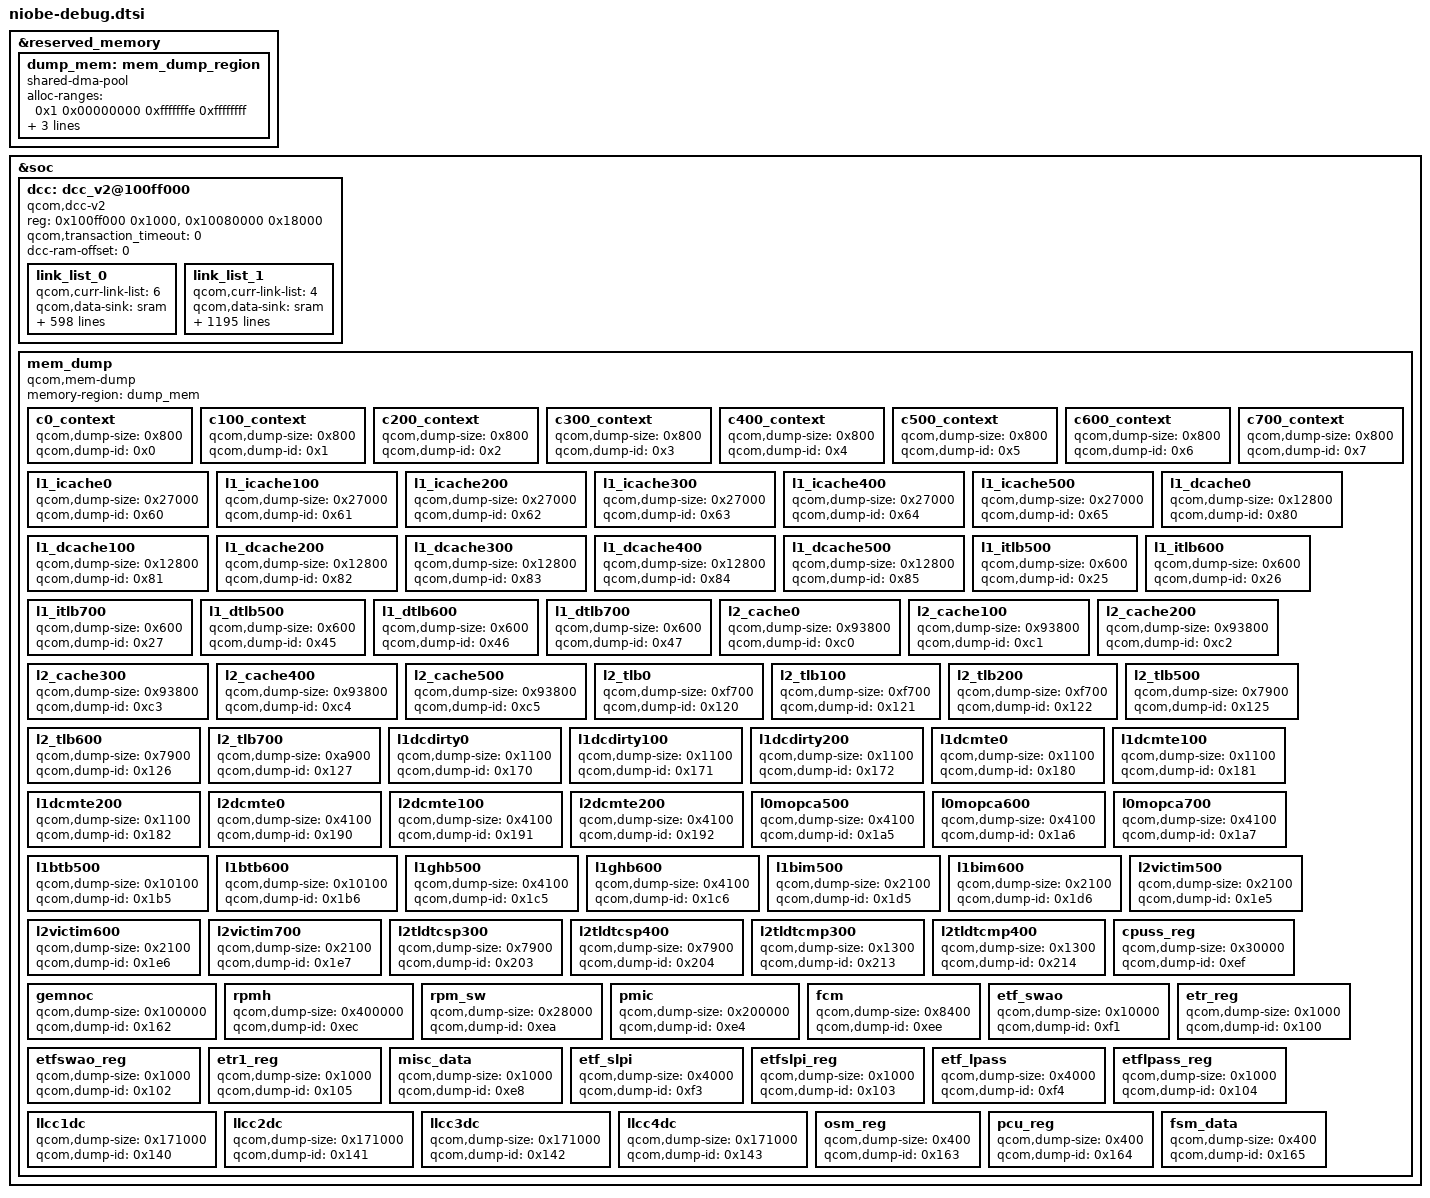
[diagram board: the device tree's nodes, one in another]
#include <dt-bindings/soc/qcom,dcc_v2.h>

&reserved_memory {
	#address-cells = <2>;
	#size-cells = <2>;
	ranges;

	dump_mem: mem_dump_region {
		compatible = "shared-dma-pool";
		alloc-ranges = <0x1 0x00000000 0xfffffffe 0xffffffff>;
		reusable;
		alignment = <0x0 0x400000>;
		size = <0 0x1800000>;
	};
};

&soc {
	dcc: dcc_v2@100ff000 {
		compatible = "qcom,dcc-v2";
		reg = <0x100ff000 0x1000>,
		      <0x10080000 0x18000>;

		qcom,transaction_timeout = <0>;

		reg-names = "dcc-base", "dcc-ram-base";
		dcc-ram-offset = <0>;

		link_list_0 {
			qcom,curr-link-list = <6>;
			qcom,data-sink = "sram";
			qcom,ap-qad-override;
			qcom,link-list = <DCC_READ 0x17421000 2 0>,
				<DCC_READ 0x3da0074 1 0>,
				<DCC_READ 0x3da0474 1 0>,
				<DCC_READ 0x3da0070 1 0>,
				<DCC_READ 0x15000474 1 0>,
				<DCC_READ 0x15000074 1 0>,
				<DCC_READ 0x15000070 1 0>,
				<DCC_READ 0x0c222004 1 0>,
				<DCC_READ 0x0c228014 1 0>,
				<DCC_READ 0x0c2280e0 1 0>,
				<DCC_READ 0x0c2280ec 1 0>,
				<DCC_READ 0x0c2280a0 16 0>,
				<DCC_READ 0x0c2280e8 1 0>,
				<DCC_READ 0x0c22813c 1 0>,
				<DCC_READ 0x0c223004 1 0>,
				<DCC_READ 0x0c229014 1 0>,
				<DCC_READ 0x0c2290e0 1 0>,
				<DCC_READ 0x0c2290ec 1 0>,
				<DCC_READ 0x0c2290a0 16 0>,
				<DCC_READ 0x0c2290e8 1 0>,
				<DCC_READ 0x0c22913c 1 0>,
				<DCC_READ 0x0c224004 1 0>,
				<DCC_READ 0x0c22a014 1 0>,
				<DCC_READ 0x0c22a0e0 1 0>,
				<DCC_READ 0x0c22a0ec 1 0>,
				<DCC_READ 0x0c22a0a0 16 0>,
				<DCC_READ 0x0c22a0e8 1 0>,
				<DCC_READ 0x0c22a13c 1 0>,
				<DCC_READ 0x17b70220 6 0>,
				<DCC_READ 0x17b702a0 6 0>,
				<DCC_READ 0x17b70320 1 0>,
				<DCC_READ 0x17b704a0 16 0>,
				<DCC_READ 0x17b70520 1 0>,
				<DCC_READ 0x17b70524 1 0>,
				<DCC_READ 0x17b70588 1 0>,
				<DCC_READ 0x17b70630 2 0>,
				<DCC_READ 0x17b70638 2 0>,
				<DCC_READ 0x17b70640 2 0>,
				<DCC_READ 0x17b71010 24 0>,
				<DCC_READ 0x17b71310 16 0>,
				<DCC_READ 0x17b71390 16 0>,
				<DCC_READ 0x17b72090 8 0>,
				<DCC_READ 0x17b744a0 16 0>,
				<DCC_READ 0x17b74520 1 0>,
				<DCC_READ 0x17b74588 1 0>,
				<DCC_READ 0x17b74630 2 0>,
				<DCC_READ 0x17b74638  2>,
				<DCC_READ 0x17b74640 2 0>,
				<DCC_READ 0x17b75010 24 0>,
				<DCC_READ 0x17b75310 16 0>,
				<DCC_READ 0x17b75390 16 0>,
				<DCC_READ 0x17b76090 8 0>,
				<DCC_READ 0xec80010 1 0>,
				<DCC_READ 0xec81000 1 0>,
				<DCC_READ 0xec81010 16 0>,
				<DCC_READ 0xec81050 4 0>,
				<DCC_READ 0xec81090 16 0>,
				<DCC_READ 0xec810d0 16 0>,
				<DCC_READ 0xec81110 16 0>,
				<DCC_READ 0xec81150 16 0>,
				<DCC_READ 0xec81550 1 0>,
				<DCC_READ 0x17800058 1 0>,
				<DCC_READ 0x17810058 1 0>,
				<DCC_READ 0x17820058 1 0>,
				<DCC_READ 0x17830058 1 0>,
				<DCC_READ 0x17840058 1 0>,
				<DCC_READ 0x17850058 1 0>,
				<DCC_READ 0x1780005c 1 0>,
				<DCC_READ 0x1781005c 1 0>,
				<DCC_READ 0x1782005c 1 0>,
				<DCC_READ 0x1783005c 1 0>,
				<DCC_READ 0x1784005c 1 0>,
				<DCC_READ 0x1785005c 1 0>,
				<DCC_READ 0x17800060 1 0>,
				<DCC_READ 0x17810060 1 0>,
				<DCC_READ 0x17820060 1 0>,
				<DCC_READ 0x17830060 1 0>,
				<DCC_READ 0x17840060 1 0>,
				<DCC_READ 0x17850060 1 0>,
				<DCC_READ 0x17800064 1 0>,
				<DCC_READ 0x17810064 1 0>,
				<DCC_READ 0x17820064 1 0>,
				<DCC_READ 0x17830064 1 0>,
				<DCC_READ 0x17840064 1 0>,
				<DCC_READ 0x17850064 1 0>,
				<DCC_READ 0x1740003c 1 0>,
				<DCC_READ 0x17a80000 1 0>,
				<DCC_READ 0x17a8002c 1 0>,
				<DCC_READ 0x17a84000 1 0>,
				<DCC_READ 0x17a8402c 1 0>,
				<DCC_READ 0x240a0000 1 0>,
				<DCC_READ 0x240a0004 1 0>,
				<DCC_READ 0x240a1000 1 0>,
				<DCC_READ 0x240a1004 1 0>,
				<DCC_READ 0xc201244 1 0>,
				<DCC_READ 0xc202244 1 0>,
				<DCC_READ 0x17ba3a84 2 0>,
				<DCC_READ 0x17b93a84 1 0>,
				<DCC_READ 0x17b00000 70 0>,
				<DCC_READ 0x17900908 1 0>,
				<DCC_READ 0x17900c18 1 0>,
				<DCC_READ 0x17901908 1 0>,
				<DCC_READ 0x17901c18 1 0>,
				<DCC_READ 0x17b90810 1 0>,
				<DCC_READ 0x17b90814 1 0>,
				<DCC_READ 0x17b90818 1 0>,
				<DCC_READ 0x17ba0810 1 0>,
				<DCC_READ 0x17ba0814 1 0>,
				<DCC_READ 0x17ba0818 1 0>,
				<DCC_READ 0x17b93500 40 0>,
				<DCC_READ 0x17ba3500 40 0>,
				<DCC_READ 0x17a80000 16 0>,
				<DCC_READ 0x17a82000 6 0>,
				<DCC_READ 0x17a84000 16 0>,
				<DCC_READ 0x17a86000 6 0>,
				<DCC_READ 0x17a88000 16 0>,
				<DCC_READ 0x17a8a000 6 0>,
				<DCC_READ 0x17800010  0>,
				<DCC_READ 0x17800024  0>,
				<DCC_READ 0x17800038 6 0>,
				<DCC_READ 0x17800058 4 0>,
				<DCC_READ 0x1780006c  0>,
				<DCC_READ 0x178000f0 2 0>,
				<DCC_READ 0x17810010  0>,
				<DCC_READ 0x17810024  0>,
				<DCC_READ 0x17810038 6 0>,
				<DCC_READ 0x17810058 4 0>,
				<DCC_READ 0x1781006c  0>,
				<DCC_READ 0x178100f0 2 0>,
				<DCC_READ 0x17820010  0>,
				<DCC_READ 0x17820024  0>,
				<DCC_READ 0x17820038 6 0>,
				<DCC_READ 0x17820058 4 0>,
				<DCC_READ 0x1782006c  0>,
				<DCC_READ 0x178200f0 2 0>,
				<DCC_READ 0x17830010  0>,
				<DCC_READ 0x17830024  0>,
				<DCC_READ 0x17830038 6 0>,
				<DCC_READ 0x17830058 4 0>,
				<DCC_READ 0x1783006c  0>,
				<DCC_READ 0x178300f0 2 0>,
				<DCC_READ 0x17840010  0>,
				<DCC_READ 0x17840010  0>,
				<DCC_READ 0x17840024  0>,
				<DCC_READ 0x17840038 6 0>,
				<DCC_READ 0x17840058 4 0>,
				<DCC_READ 0x1784006c  0>,
				<DCC_READ 0x178400f0 2 0>,
				<DCC_READ 0x17850024  0>,
				<DCC_READ 0x17850038 6 0>,
				<DCC_READ 0x17850058 4 0>,
				<DCC_READ 0x1785006c  0>,
				<DCC_READ 0x178500f0 2 0>,
				<DCC_READ 0x17880010  0>,
				<DCC_READ 0x17880024  0>,
				<DCC_READ 0x1788003c 5 0>,
				<DCC_READ 0x1788006c 7 0>,
				<DCC_READ 0x17880090 5 0>,
				<DCC_READ 0x178800e0 23 0>,
				<DCC_READ 0x17880140 2 0>,
				<DCC_READ 0x1788019c 2 0>,
				<DCC_READ 0x178801b4 6 0>,
				<DCC_READ 0x178801f0 5 0>,
				<DCC_READ 0x17880250 4 0>,
				<DCC_READ 0x17200104 29 0>,
				<DCC_READ 0x17200204 29 0>,
				<DCC_READ 0x17200384 29 0>,
				<DCC_READ 0x17220000 1 0>,
				<DCC_READ 0x17220008 1 0>,
				<DCC_READ 0x17220010 1 0>,
				<DCC_READ 0x17220018 1 0>,
				<DCC_READ 0x17220020 1 0>,
				<DCC_READ 0x17220028 1 0>,
				<DCC_READ 0x17220040 1 0>,
				<DCC_READ 0x17220048 1 0>,
				<DCC_READ 0x17220050 1 0>,
				<DCC_READ 0x17220060 1 0>,
				<DCC_READ 0x17220068 1 0>,
				<DCC_READ 0x17220080 1 0>,
				<DCC_READ 0x17220088 1 0>,
				<DCC_READ 0x17220090 1 0>,
				<DCC_READ 0x172200a0 1 0>,
				<DCC_READ 0x172200a8 1 0>,
				<DCC_READ 0x172200c0 1 0>,
				<DCC_READ 0x172200c8 1 0>,
				<DCC_READ 0x172200d0 1 0>,
				<DCC_READ 0x172200e0 1 0>,
				<DCC_READ 0x172200e8 1 0>,
				<DCC_READ 0x17220100 1 0>,
				<DCC_READ 0x17220108 1 0>,
				<DCC_READ 0x17220110 1 0>,
				<DCC_READ 0x17220120 1 0>,
				<DCC_READ 0x17220128 1 0>,
				<DCC_READ 0x17220140 1 0>,
				<DCC_READ 0x17220148 1 0>,
				<DCC_READ 0x17220150 1 0>,
				<DCC_READ 0x17220160 1 0>,
				<DCC_READ 0x17220168 1 0>,
				<DCC_READ 0x17220180 1 0>,
				<DCC_READ 0x17220188 1 0>,
				<DCC_READ 0x17220190 1 0>,
				<DCC_READ 0x172201a0 1 0>,
				<DCC_READ 0x172201a8 1 0>,
				<DCC_READ 0x172201c0 1 0>,
				<DCC_READ 0x172201c8 1 0>,
				<DCC_READ 0x172201d0 1 0>,
				<DCC_READ 0x172201e0 1 0>,
				<DCC_READ 0x172201e8 1 0>,
				<DCC_READ 0x17220200 1 0>,
				<DCC_READ 0x17220208 1 0>,
				<DCC_READ 0x17220210 1 0>,
				<DCC_READ 0x17220220 1 0>,
				<DCC_READ 0x17220228 1 0>,
				<DCC_READ 0x17220240 1 0>,
				<DCC_READ 0x17220248 1 0>,
				<DCC_READ 0x17220250 1 0>,
				<DCC_READ 0x17220260 1 0>,
				<DCC_READ 0x17220268 1 0>,
				<DCC_READ 0x17220280 1 0>,
				<DCC_READ 0x17220288 1 0>,
				<DCC_READ 0x17220290 1 0>,
				<DCC_READ 0x172202a0 1 0>,
				<DCC_READ 0x172202a8 1 0>,
				<DCC_READ 0x172202c0 1 0>,
				<DCC_READ 0x172202c8 1 0>,
				<DCC_READ 0x172202d0 1 0>,
				<DCC_READ 0x172202e0 1 0>,
				<DCC_READ 0x172202e8 1 0>,
				<DCC_READ 0x17220300 1 0>,
				<DCC_READ 0x17220308 1 0>,
				<DCC_READ 0x17220310 1 0>,
				<DCC_READ 0x17220320 1 0>,
				<DCC_READ 0x17220328 1 0>,
				<DCC_READ 0x17220340 1 0>,
				<DCC_READ 0x17220348 1 0>,
				<DCC_READ 0x17220350 1 0>,
				<DCC_READ 0x17220360 1 0>,
				<DCC_READ 0x17220368 1 0>,
				<DCC_READ 0x1722e000 1 0>,
				<DCC_READ 0x17d80100 200 0>,
				<DCC_READ 0x17d9001c 1 0>,
				<DCC_READ 0x17d900dc 1 0>,
				<DCC_READ 0x17d900e8 1 0>,
				<DCC_READ 0x17d90320 1 0>,
				<DCC_READ 0x17d9101c 1 0>,
				<DCC_READ 0x17d910dc 1 0>,
				<DCC_READ 0x17d910e8 1 0>,
				<DCC_READ 0x17d91320 1 0>,
				<DCC_READ 0x17d9201c 1 0>,
				<DCC_READ 0x17d920dc 1 0>,
				<DCC_READ 0x17d920e8 1 0>,
				<DCC_READ 0x17d92320 1 0>,
				<DCC_READ 0x17d9034c 1 0>,
				<DCC_READ 0x17d9134c 1 0>,
				<DCC_READ 0x17d9234c 1 0>,
				<DCC_READ 0x17880054 1 0>,
				<DCC_READ 0x17880000 1 0>,
				<DCC_READ 0x17a80000 1 0>,
				<DCC_READ 0x17d80000 3 0>,
				<DCC_READ 0x17d80010 2 0>,
				<DCC_READ 0x17d90000 4 0>,
				<DCC_READ 0x17d90014 2 0>,
				<DCC_READ 0x17d90024 22 0>,
				<DCC_READ 0x17d90080 5 0>,
				<DCC_READ 0x17d900b0 1 0>,
				<DCC_READ 0x17d900b8 2 0>,
				<DCC_READ 0x17d900d0 3 0>,
				<DCC_READ 0x17d900e0 2 0>,
				<DCC_READ 0x17d900ec 2 0>,
				<DCC_READ 0x17d90100 40 0>,
				<DCC_READ 0x17d90200 40 0>,
				<DCC_READ 0x17d90304 4 0>,
				<DCC_READ 0x17d90350 30 0>,
				<DCC_READ 0x17d903e0 2 0>,
				<DCC_READ 0x17d90404 1 0>,
				<DCC_READ 0x17d91000 2 0>,
				<DCC_READ 0x17d91014 2 0>,
				<DCC_READ 0x17d91024 22 0>,
				<DCC_READ 0x17d91080 6 0>,
				<DCC_READ 0x17d910b0 1 0>,
				<DCC_READ 0x17d910b8 2 0>,
				<DCC_READ 0x17d910d0 3 0>,
				<DCC_READ 0x17d910e0 2 0>,
				<DCC_READ 0x17d910ec 2 0>,
				<DCC_READ 0x17d91100 40 0>,
				<DCC_READ 0x17d91200 40 0>,
				<DCC_READ 0x17d91304 4 0>,
				<DCC_READ 0x17d91324 1 0>,
				<DCC_READ 0x17d91350 32 0>,
				<DCC_READ 0x17d913e0 3 0>,
				<DCC_READ 0x17d91404 1 0>,
				<DCC_READ 0x17d92000 4 0>,
				<DCC_READ 0x17d92014 2 0>,
				<DCC_READ 0x17d92024 22 0>,
				<DCC_READ 0x17d92080 7 0>,
				<DCC_READ 0x17d920b0 1 0>,
				<DCC_READ 0x17d920b8 2 0>,
				<DCC_READ 0x17d920d0 3 0>,
				<DCC_READ 0x17d920e0 2 0>,
				<DCC_READ 0x17d920ec 2 0>,
				<DCC_READ 0x17d92100 40 0>,
				<DCC_READ 0x17d92200 40 0>,
				<DCC_READ 0x17d92304 4 0>,
				<DCC_READ 0x17d92324 2 0>,
				<DCC_READ 0x17d92350 33 0>,
				<DCC_READ 0x17d923e0 4 0>,
				<DCC_READ 0x17d92404 1 0>,
				<DCC_READ 0x17d98000 8 0>,
				<DCC_READ 0x17d98020 2 0>,
				<DCC_READ 0x17d90020 1 0>,
				<DCC_READ 0x17d91020 1 0>,
				<DCC_READ 0x17d92020 1 0>,
				<DCC_READ 0x17d90300 1 0>,
				<DCC_READ 0x17d90340 1 0>,
				<DCC_READ 0x17d90410 1 0>,
				<DCC_READ 0x17d91008 1 0>,
				<DCC_READ 0x17d9100c 1 0>,
				<DCC_READ 0x17d91300 1 0>,
				<DCC_READ 0x17d91340 1 0>,
				<DCC_READ 0x17d91410 1 0>,
				<DCC_READ 0x17d92300 1 0>,
				<DCC_READ 0x17d92340 1 0>,
				<DCC_READ 0x17d92410 1 0>,
				<DCC_READ 0x17d8000c 1 0>,
				<DCC_READ 0x17d80018 1 0>,
				<DCC_READ 0xb200110  0>,
				<DCC_READ 0xb200900  0>,
				<DCC_READ 0xb201020 2 0>,
				<DCC_READ 0xb201030  0>,
				<DCC_READ 0xb20103c  0>,
				<DCC_READ 0xb201200 3 0>,
				<DCC_READ 0xb204510 2 0>,
				<DCC_READ 0xb204520  0>,
				<DCC_READ 0xb211024  0>,
				<DCC_READ 0xb221024  0>,
				<DCC_READ 0xb231024  0>,
				<DCC_READ 0x17a00010  0>,
				<DCC_READ 0x17a00030  0>,
				<DCC_READ 0x17a00038  0>,
				<DCC_READ 0x17a00040  0>,
				<DCC_READ 0x17a00048  0>,
				<DCC_READ 0x17a00400 3 0>,
				<DCC_READ 0x17a00408  0>,
				<DCC_READ 0xc2a8070 1 0>,
				<DCC_READ 0xc2a8074 1 0>,
				<DCC_READ 0xc2a8078 1 0>,
				<DCC_READ 0x123140 1 0>,
				<DCC_READ 0x11c004 2 0>,
				<DCC_READ 0x110018 5 0>,
				<DCC_READ 0x110030  0>,
				<DCC_READ 0x11c018 5 0>,
				<DCC_READ 0x11c030  0>,
				<DCC_READ 0x178040  0>,
				<DCC_READ 0x199014 5 0>,
				<DCC_READ 0x19902c  0>,
				<DCC_READ 0x19d014 5 0>,
				<DCC_READ 0x19d02c  0>,
				<DCC_READ 0x10c0000 4 0>,
				<DCC_READ 0x10c1000 2 0>,
				<DCC_READ 0x10c1010 7 0>,
				<DCC_READ 0x10c1100 3 0>,
				<DCC_READ 0x10c1110 5 0>,
				<DCC_READ 0x10c1130 2 0>,
				<DCC_READ 0x10c113c 2 0>,
				<DCC_READ 0x10c1148 3 0>,
				<DCC_READ 0x15002204  0>,
				<DCC_READ 0x150025dc  0>,
				<DCC_READ 0x15002670  0>,
				<DCC_READ 0x3da26b4  0>,
				<DCC_READ 0x126010 2 0>,
				<DCC_READ 0xadf0004 2 0>,
				<DCC_READ 0xadf0018 2 0>,
				<DCC_READ 0xadf0030 3 0>,
				<DCC_READ 0xadf004c 3 0>,
				<DCC_READ 0xadf0068  0>,
				<DCC_READ 0xadf0074  0>,
				<DCC_READ 0xadf0080 2 0>,
				<DCC_READ 0xadf0094 2 0>,
				<DCC_READ 0xadf00ac  0>,
				<DCC_READ 0xadf00b8 2 0>,
				<DCC_READ 0xadf00d0 3 0>,
				<DCC_READ 0xadf1004 2 0>,
				<DCC_READ 0xadf1018 2 0>,
				<DCC_READ 0xadf1030  0>,
				<DCC_READ 0xadf103c  0>,
				<DCC_READ 0xadf1048 3 0>,
				<DCC_READ 0xadf2004 2 0>,
				<DCC_READ 0xadf2018 2 0>,
				<DCC_READ 0xadf2030  0>,
				<DCC_READ 0xadf203c  0>,
				<DCC_READ 0xadf2048  0>,
				<DCC_READ 0xadf3000 2 0>,
				<DCC_READ 0xadf3018  0>,
				<DCC_READ 0xadf3024 3 0>,
				<DCC_READ 0xadf3040  0>,
				<DCC_READ 0xadf304c 4 0>,
				<DCC_READ 0xadf306c  0>,
				<DCC_READ 0xadf309c 2 0>,
				<DCC_READ 0xadf30b4  0>,
				<DCC_READ 0xadf30c0  0>,
				<DCC_READ 0xadf316c  0>,
				<DCC_READ 0xadf319c  0>,
				<DCC_READ 0xadf31a8 2 0>,
				<DCC_READ 0xadf31c0  0>,
				<DCC_READ 0xadf4020 3 0>,
				<DCC_READ 0xadf4038  0>,
				<DCC_READ 0xadf5170  0>,
				<DCC_READ 0x221c00a0 1 0>,
				<DCC_READ 0x221c00a4 1 0>,
				<DCC_READ 0x17400038 1 0>,
				<DCC_READ 0x17d98010 1 0>,
				<DCC_READ 0x1fc8000 1 0>,
				<DCC_READ 0x221c20a4 1 0>,
				<DCC_READ 0x129000  0>,
				<DCC_READ 0x12903c  0>,
				<DCC_READ 0x171004  0>,
				<DCC_READ 0x17100c 5 0>,
				<DCC_READ 0x171150  0>,
				<DCC_READ 0x17b000  0>,
				<DCC_READ 0x17b03c  0>,
				<DCC_READ 0x17c000  0>,
				<DCC_READ 0x17c03c  0>,
				<DCC_READ 0x17d000  0>,
				<DCC_READ 0x17d03c  0>,
				<DCC_READ 0x17e000  0>,
				<DCC_READ 0x17e03c  0>,
				<DCC_READ 0x186000  0>,
				<DCC_READ 0x18603c  0>,
				<DCC_READ 0x3d00000  0>,
				<DCC_READ 0x3d00008  0>,
				<DCC_READ 0x3d00020 6 0>,
				<DCC_READ 0x3d00040 4 0>,
				<DCC_READ 0x3d00054 2 0>,
				<DCC_READ 0x3d00060  0>,
				<DCC_READ 0x3d00068  0>,
				<DCC_READ 0x3d00070  0>,
				<DCC_READ 0x3d000a0 4 0>,
				<DCC_READ 0x3d000b4 13 0>,
				<DCC_READ 0x3d00100 20 0>,
				<DCC_READ 0x3d00188 5 0>,
				<DCC_READ 0x3d001a4 6 0>,
				<DCC_READ 0x3d001c4 2 0>,
				<DCC_READ 0x3d001d0  0>,
				<DCC_READ 0x3d001d8 2 0>,
				<DCC_READ 0x3d001fc 28 0>,
				<DCC_READ 0x3d00274 19 0>,
				<DCC_READ 0x3d002c8 35 0>,
				<DCC_READ 0x3d0035c 12 0>,
				<DCC_READ 0x3d00394 2 0>,
				<DCC_READ 0x3d003a4 9 0>,
				<DCC_READ 0x3d003d0 3 0>,
				<DCC_READ 0x3d003e4 16 0>,
				<DCC_READ 0x3d0042c 4 0>,
				<DCC_READ 0x3d00444  0>,
				<DCC_READ 0x3d00450 9 0>,
				<DCC_READ 0x3d0047c 3 0>,
				<DCC_READ 0x3d00494  0>,
				<DCC_READ 0x3d0049c  0>,
				<DCC_READ 0x3d004a4  0>,
				<DCC_READ 0x3d004ac 7 0>,
				<DCC_READ 0x3d004d0 5 0>,
				<DCC_READ 0x3d004e8  0>,
				<DCC_READ 0x3d004f0 4 0>,
				<DCC_READ 0x3d00508 15 0>,
				<DCC_READ 0x3d0054c 3 0>,
				<DCC_READ 0x3d00560 2 0>,
				<DCC_READ 0x3d00570  0>,
				<DCC_READ 0x3d00598 20 0>,
				<DCC_READ 0x3d00680  0>,
				<DCC_READ 0x3d00f80  0>,
				<DCC_READ 0x3d00fc0  0>,
				<DCC_READ 0x3d01100  0>,
				<DCC_READ 0x3d02000 31 0>,
				<DCC_READ 0x3d02080 4 0>,
				<DCC_READ 0x3d020d8 9 0>,
				<DCC_READ 0x3d02100 8 0>,
				<DCC_READ 0x3d0212c 5 0>,
				<DCC_READ 0x3d022c0 12 0>,
				<DCC_READ 0x3d02300 12 0>,
				<DCC_READ 0x3d0239c 5 0>,
				<DCC_READ 0x3d0f000 12 0>,
				<DCC_READ 0x3d0f100 3 0>,
				<DCC_READ 0x3d0f114 3 0>,
				<DCC_READ 0x3d0f124 6 0>,
				<DCC_READ 0x3d3c000 3 0>,
				<DCC_READ 0x3d3d000  0>,
				<DCC_READ 0x3d3e000 4 0>,
				<DCC_READ 0x3d3f000 2 0>,
				<DCC_READ 0x3d50000 21 0>,
				<DCC_READ 0x3d500d0  0>,
				<DCC_READ 0x3d500d8  0>,
				<DCC_READ 0x3d50100 3 0>,
				<DCC_READ 0x3d50110 2 0>,
				<DCC_READ 0x3d5011c  0>,
				<DCC_READ 0x3d50200 5 0>,
				<DCC_READ 0x3d50400 5 0>,
				<DCC_READ 0x3d50450  0>,
				<DCC_READ 0x3d50460 2 0>,
				<DCC_READ 0x3d50490 12 0>,
				<DCC_READ 0x3d50550  0>,
				<DCC_READ 0x3d50d00 2 0>,
				<DCC_READ 0x3d50d10  0>,
				<DCC_READ 0x3d50d18 13 0>,
				<DCC_READ 0x3d50fe0  0>,
				<DCC_READ 0x3d50ff8  0>,
				<DCC_READ 0x3d51010  0>,
				<DCC_READ 0x3d51028  0>,
				<DCC_READ 0x3d51280  0>,
				<DCC_READ 0x3d51520  0>,
				<DCC_READ 0x3d51538  0>,
				<DCC_READ 0x3d51550  0>,
				<DCC_READ 0x3d517c0  0>,
				<DCC_READ 0x3d51a60  0>,
				<DCC_READ 0x3d51a78  0>,
				<DCC_READ 0x3d51a90  0>,
				<DCC_READ 0x3d51aa8  0>,
				<DCC_READ 0x3d51d00  0>,
				<DCC_READ 0x3d51fa0  0>,
				<DCC_READ 0x3d51fb8  0>,
				<DCC_READ 0x3d52240  0>,
				<DCC_READ 0x3d52258  0>,
				<DCC_READ 0x3d524e0  0>,
				<DCC_READ 0x3d64000 13 0>,
				<DCC_READ 0x3d6403c  0>,
				<DCC_READ 0x3d66000 6 0>,
				<DCC_READ 0x3d67000  0>,
				<DCC_READ 0x3d68000 5 0>,
				<DCC_READ 0x3d68020 11 0>,
				<DCC_READ 0x3d68050  0>,
				<DCC_READ 0x3d6805c  0>,
				<DCC_READ 0x3d68064  0>,
				<DCC_READ 0x3d68088  0>,
				<DCC_READ 0x3d68090 6 0>,
				<DCC_READ 0x3d680fc 31 0>,
				<DCC_READ 0x3d68180 4 0>,
				<DCC_READ 0x3d68194 2 0>,
				<DCC_READ 0x3d681a0 15 0>,
				<DCC_READ 0x3d681e0 4 0>,
				<DCC_READ 0x3d69000 23 0>,
				<DCC_READ 0x3d69080 14 0>,
				<DCC_READ 0x3d690c0 2 0>,
				<DCC_READ 0x3d690d4  0>,
				<DCC_READ 0x3d690dc  0>,
				<DCC_READ 0x3d690e8  0>,
				<DCC_READ 0x3d69108  0>,
				<DCC_READ 0x3d69158 3 0>,
				<DCC_READ 0x3d6916c 3 0>,
				<DCC_READ 0x3d6917c 4 0>,
				<DCC_READ 0x3d7d000 12 0>,
				<DCC_READ 0x3d7d03c 3 0>,
				<DCC_READ 0x3d7d400  0>,
				<DCC_READ 0x3d7d41c  0>,
				<DCC_READ 0x3d7d424 3 0>,
				<DCC_READ 0x3d7dc58  0>,
				<DCC_READ 0x3d7dc94  0>,
				<DCC_READ 0x3d7dca4  0>,
				<DCC_READ 0x3d7dd58 2 0>,
				<DCC_READ 0x3d7df80 2 0>,
				<DCC_READ 0x3d7df90 2 0>,
				<DCC_READ 0x3d7dfa0 2 0>,
				<DCC_READ 0x3d7dfb0 2 0>,
				<DCC_READ 0x3d7e000 5 0>,
				<DCC_READ 0x3d7e01c 2 0>,
				<DCC_READ 0x3d7e02c 2 0>,
				<DCC_READ 0x3d7e03c  0>,
				<DCC_READ 0x3d7e044  0>,
				<DCC_READ 0x3d7e04c 5 0>,
				<DCC_READ 0x3d7e064 4 0>,
				<DCC_READ 0x3d7e090 13 0>,
				<DCC_READ 0x3d7e100 2 0>,
				<DCC_READ 0x3d7e130  0>,
				<DCC_READ 0x3d7e140  0>,
				<DCC_READ 0x3d7e500 2 0>,
				<DCC_READ 0x3d7e50c  0>,
				<DCC_READ 0x3d7e520  0>,
				<DCC_READ 0x3d7e53c  0>,
				<DCC_READ 0x3d7e550 2 0>,
				<DCC_READ 0x3d7e574  0>,
				<DCC_READ 0x3d7e5c0  0>,
				<DCC_READ 0x3d7e5f0 3 0>,
				<DCC_READ 0x3d7e600 2 0>,
				<DCC_READ 0x3d7e610 3 0>,
				<DCC_READ 0x3d7e648 2 0>,
				<DCC_READ 0x3d7e658 9 0>,
				<DCC_READ 0x3d7e700 16 0>,
				<DCC_READ 0x3d7e7c4  0>,
				<DCC_READ 0x3d7e7e0 3 0>,
				<DCC_READ 0x3d7e7f0  0>,
				<DCC_READ 0x3d7e800 4 0>,
				<DCC_READ 0x3d7f050  0>,
				<DCC_READ 0x3d7f060 2 0>,
				<DCC_READ 0x3d7f080  0>,
				<DCC_READ 0x3d7f090 3 0>,
				<DCC_READ 0x3d80080  0>,
				<DCC_READ 0x3d800d0 3 0>,
				<DCC_READ 0x3d80c80 3 0>,
				<DCC_READ 0x3d80c90 3 0>,
				<DCC_READ 0x3d80ca0 3 0>,
				<DCC_READ 0x3d80d40  0>,
				<DCC_READ 0x3d8e100 8 0>,
				<DCC_READ 0x3d8ec00 2 0>,
				<DCC_READ 0x3d8ec0c  0>,
				<DCC_READ 0x3d8ec14 10 0>,
				<DCC_READ 0x3d8ec40 4 0>,
				<DCC_READ 0x3d8ec54 2 0>,
				<DCC_READ 0x3d8eca0  0>,
				<DCC_READ 0x3d8ecc0  0>,
				<DCC_READ 0x3d9200c 3 0>,
				<DCC_READ 0x3d93000  0>,
				<DCC_READ 0x3d94000 3 0>,
				<DCC_READ 0x3d95000 5 0>,
				<DCC_READ 0x3d96000 5 0>,
				<DCC_READ 0x3d97000 5 0>,
				<DCC_READ 0x3d98000 5 0>,
				<DCC_READ 0x3d99000 7 0>,
				<DCC_READ 0x3d99054 9 0>,
				<DCC_READ 0x3d9907c 25 0>,
				<DCC_READ 0x3d990e4 3 0>,
				<DCC_READ 0x3d990f4 3 0>,
				<DCC_READ 0x3d9910c  0>,
				<DCC_READ 0x3d991e0 3 0>,
				<DCC_READ 0x3d99224 2 0>,
				<DCC_READ 0x3d99270 3 0>,
				<DCC_READ 0x3d99280 2 0>,
				<DCC_READ 0x3d99314 3 0>,
				<DCC_READ 0x3d993a0 3 0>,
				<DCC_READ 0x3d993e4 4 0>,
				<DCC_READ 0x3d9942c  0>,
				<DCC_READ 0x3d99470 3 0>,
				<DCC_READ 0x3d99500 12 0>,
				<DCC_READ 0x3d99550 3 0>,
				<DCC_READ 0x3d99560 5 0>,
				<DCC_READ 0x3d99578 2 0>,
				<DCC_READ 0x3d9958c  0>,
				<DCC_READ 0x3d995b4 7 0>,
				<DCC_READ 0x3d995d8  0>,
				<DCC_READ 0x3d995e0 3 0>,
				<DCC_READ 0x3d9e000  0>,
				<DCC_READ 0x3d9e040 5 0>,
				<DCC_READ 0x3d9e080 5 0>,
				<DCC_READ 0x3d9e0a0 3 0>,
				<DCC_READ 0x3d9e0c8 11 0>,
				<DCC_READ 0x3d9e0f8 26 0>,
				<DCC_READ 0x3d9e200 4 0>,
				<DCC_READ 0x3d9f000 2 0>,
				<DCC_READ 0x17421000 2 0>;
		};

		link_list_1 {
			qcom,curr-link-list = <4>;
			qcom,data-sink = "sram";
			qcom,ap-qad-override;
			qcom,link-list = <DCC_READ 0x17421000 2 0>,
				<DCC_READ 0x3da0074 1 0>,
				<DCC_READ 0x3da0474 1 0>,
				<DCC_READ 0x3da0070 1 0>,
				<DCC_READ 0x15000474 1 0>,
				<DCC_READ 0x15000074 1 0>,
				<DCC_READ 0x15000070 1 0>,
				<DCC_READ 0x2407701c  0>,
				<DCC_READ 0x24077030  0>,
				<DCC_READ 0x2408005c  0>,
				<DCC_READ 0x240800c8  0>,
				<DCC_READ 0x240800d4  0>,
				<DCC_READ 0x240800e0  0>,
				<DCC_READ 0x240800ec  0>,
				<DCC_READ 0x240800f8  0>,
				<DCC_READ 0x240801b4  0>,
				<DCC_READ 0x240a8120 5 0>,
				<DCC_READ 0x240a8144 2 0>,
				<DCC_READ 0x240a81c4 4 0>,
				<DCC_READ 0x240a81e4  0>,
				<DCC_READ 0x240a81f0  0>,
				<DCC_READ 0x240a81fc  0>,
				<DCC_READ 0x240a8208  0>,
				<DCC_READ 0x240a8258  0>,
				<DCC_READ 0x240a8278  0>,
				<DCC_READ 0x240a82e8  0>,
				<DCC_READ 0x240a8860 3 0>,
				<DCC_READ 0x240aa034 3 0>,
				<DCC_READ 0x240ba28c  0>,
				<DCC_READ 0x240ba294  0>,
				<DCC_READ 0x240ba29c  0>,
				<DCC_READ 0x24185100 4 0>,
				<DCC_READ 0x24187100  0>,
				<DCC_READ 0x2418c100  0>,
				<DCC_READ 0x24401e64  0>,
				<DCC_READ 0x24401ea0  0>,
				<DCC_READ 0x24403e64  0>,
				<DCC_READ 0x24403ea0  0>,
				<DCC_READ 0x2440527c  0>,
				<DCC_READ 0x24405290  0>,
				<DCC_READ 0x244054ec  0>,
				<DCC_READ 0x244054f4  0>,
				<DCC_READ 0x24405514  0>,
				<DCC_READ 0x2440551c  0>,
				<DCC_READ 0x24405524  0>,
				<DCC_READ 0x24405548  0>,
				<DCC_READ 0x24405550  0>,
				<DCC_READ 0x24405558  0>,
				<DCC_READ 0x244055b8  0>,
				<DCC_READ 0x244055c0  0>,
				<DCC_READ 0x244055ec  0>,
				<DCC_READ 0x24405688  0>,
				<DCC_READ 0x24405870  0>,
				<DCC_READ 0x244058a0  0>,
				<DCC_READ 0x244058a8  0>,
				<DCC_READ 0x244058b0  0>,
				<DCC_READ 0x244058b8  0>,
				<DCC_READ 0x244058d8 2 0>,
				<DCC_READ 0x244058f4  0>,
				<DCC_READ 0x244058fc  0>,
				<DCC_READ 0x24405920  0>,
				<DCC_READ 0x24405928  0>,
				<DCC_READ 0x24405944  0>,
				<DCC_READ 0x24406604  0>,
				<DCC_READ 0x2440660c  0>,
				<DCC_READ 0x24407010  0>,
				<DCC_READ 0x24440310  0>,
				<DCC_READ 0x24440400 2 0>,
				<DCC_READ 0x24440410 3 0>,
				<DCC_READ 0x24440428  0>,
				<DCC_READ 0x24440430  0>,
				<DCC_READ 0x24440440  0>,
				<DCC_READ 0x24440448  0>,
				<DCC_READ 0x244404a0  0>,
				<DCC_READ 0x244404b0 3 0>,
				<DCC_READ 0x244404d0 2 0>,
				<DCC_READ 0x2444341c  0>,
				<DCC_READ 0x24445804  0>,
				<DCC_READ 0x2444590c  0>,
				<DCC_READ 0x24445a14  0>,
				<DCC_READ 0x24445c1c  0>,
				<DCC_READ 0x24445c38  0>,
				<DCC_READ 0x24449100  0>,
				<DCC_READ 0x24449110  0>,
				<DCC_READ 0x24449120  0>,
				<DCC_READ 0x24449180 2 0>,
				<DCC_READ 0x24460618  0>,
				<DCC_READ 0x24460684  0>,
				<DCC_READ 0x2446068c  0>,
				<DCC_READ 0x24481e64  0>,
				<DCC_READ 0x24481ea0  0>,
				<DCC_READ 0x24483e64  0>,
				<DCC_READ 0x24483ea0  0>,
				<DCC_READ 0x2448527c  0>,
				<DCC_READ 0x24485290  0>,
				<DCC_READ 0x244854ec  0>,
				<DCC_READ 0x244854f4  0>,
				<DCC_READ 0x24485514  0>,
				<DCC_READ 0x2448551c  0>,
				<DCC_READ 0x24485524  0>,
				<DCC_READ 0x24485548  0>,
				<DCC_READ 0x24485550  0>,
				<DCC_READ 0x24485558  0>,
				<DCC_READ 0x244855b8  0>,
				<DCC_READ 0x244855c0  0>,
				<DCC_READ 0x244855ec  0>,
				<DCC_READ 0x24485688  0>,
				<DCC_READ 0x24485870  0>,
				<DCC_READ 0x244858a0  0>,
				<DCC_READ 0x244858a8  0>,
				<DCC_READ 0x244858b0  0>,
				<DCC_READ 0x244858b8  0>,
				<DCC_READ 0x244858d8 2 0>,
				<DCC_READ 0x244858f4  0>,
				<DCC_READ 0x244858fc  0>,
				<DCC_READ 0x24485920  0>,
				<DCC_READ 0x24485928  0>,
				<DCC_READ 0x24485944  0>,
				<DCC_READ 0x24486604  0>,
				<DCC_READ 0x2448660c  0>,
				<DCC_READ 0x24487010  0>,
				<DCC_READ 0x244c0310  0>,
				<DCC_READ 0x244c0400 2 0>,
				<DCC_READ 0x244c0410 3 0>,
				<DCC_READ 0x244c0428  0>,
				<DCC_READ 0x244c0430  0>,
				<DCC_READ 0x244c0440  0>,
				<DCC_READ 0x244c0448  0>,
				<DCC_READ 0x244c04a0  0>,
				<DCC_READ 0x244c04b0 3 0>,
				<DCC_READ 0x244c04d0 2 0>,
				<DCC_READ 0x244c341c  0>,
				<DCC_READ 0x244c5804  0>,
				<DCC_READ 0x244c590c  0>,
				<DCC_READ 0x244c5a14  0>,
				<DCC_READ 0x244c5c1c  0>,
				<DCC_READ 0x244c5c38  0>,
				<DCC_READ 0x244c9100  0>,
				<DCC_READ 0x244c9110  0>,
				<DCC_READ 0x244c9120  0>,
				<DCC_READ 0x244c9180 2 0>,
				<DCC_READ 0x244e0618  0>,
				<DCC_READ 0x244e0684  0>,
				<DCC_READ 0x244e068c  0>,
				<DCC_READ 0x24601e64  0>,
				<DCC_READ 0x24601ea0  0>,
				<DCC_READ 0x24603e64  0>,
				<DCC_READ 0x24603ea0  0>,
				<DCC_READ 0x2460527c  0>,
				<DCC_READ 0x24605290  0>,
				<DCC_READ 0x246054ec  0>,
				<DCC_READ 0x246054f4  0>,
				<DCC_READ 0x24605514  0>,
				<DCC_READ 0x2460551c  0>,
				<DCC_READ 0x24605524  0>,
				<DCC_READ 0x24605548  0>,
				<DCC_READ 0x24605550  0>,
				<DCC_READ 0x24605558  0>,
				<DCC_READ 0x246055b8  0>,
				<DCC_READ 0x246055c0  0>,
				<DCC_READ 0x246055ec  0>,
				<DCC_READ 0x24605688  0>,
				<DCC_READ 0x24605870  0>,
				<DCC_READ 0x246058a0  0>,
				<DCC_READ 0x246058a8  0>,
				<DCC_READ 0x246058b0  0>,
				<DCC_READ 0x246058b8  0>,
				<DCC_READ 0x246058d8 2 0>,
				<DCC_READ 0x246058f4  0>,
				<DCC_READ 0x246058fc  0>,
				<DCC_READ 0x24605920  0>,
				<DCC_READ 0x24605928  0>,
				<DCC_READ 0x24605944  0>,
				<DCC_READ 0x24606604  0>,
				<DCC_READ 0x2460660c  0>,
				<DCC_READ 0x24607010  0>,
				<DCC_READ 0x24640310  0>,
				<DCC_READ 0x24640400 2 0>,
				<DCC_READ 0x24640410 3 0>,
				<DCC_READ 0x24640428  0>,
				<DCC_READ 0x24640430  0>,
				<DCC_READ 0x24640440  0>,
				<DCC_READ 0x24640448  0>,
				<DCC_READ 0x246404a0  0>,
				<DCC_READ 0x246404b0 3 0>,
				<DCC_READ 0x246404d0 2 0>,
				<DCC_READ 0x2464341c  0>,
				<DCC_READ 0x24645804  0>,
				<DCC_READ 0x2464590c  0>,
				<DCC_READ 0x24645a14  0>,
				<DCC_READ 0x24645c1c  0>,
				<DCC_READ 0x24645c38  0>,
				<DCC_READ 0x24649100  0>,
				<DCC_READ 0x24649110  0>,
				<DCC_READ 0x24649120  0>,
				<DCC_READ 0x24649180 2 0>,
				<DCC_READ 0x24660618  0>,
				<DCC_READ 0x24660684  0>,
				<DCC_READ 0x2466068c  0>,
				<DCC_READ 0x24681e64  0>,
				<DCC_READ 0x24681ea0  0>,
				<DCC_READ 0x24683e64  0>,
				<DCC_READ 0x24683ea0  0>,
				<DCC_READ 0x2468527c  0>,
				<DCC_READ 0x24685290  0>,
				<DCC_READ 0x246854ec  0>,
				<DCC_READ 0x246854f4  0>,
				<DCC_READ 0x24685514  0>,
				<DCC_READ 0x2468551c  0>,
				<DCC_READ 0x24685524  0>,
				<DCC_READ 0x24685548  0>,
				<DCC_READ 0x24685550  0>,
				<DCC_READ 0x24685558  0>,
				<DCC_READ 0x246855b8  0>,
				<DCC_READ 0x246855c0  0>,
				<DCC_READ 0x246855ec  0>,
				<DCC_READ 0x24685688  0>,
				<DCC_READ 0x24685870  0>,
				<DCC_READ 0x246858a0  0>,
				<DCC_READ 0x246858a8  0>,
				<DCC_READ 0x246858b0  0>,
				<DCC_READ 0x246858b8  0>,
				<DCC_READ 0x246858d8 2 0>,
				<DCC_READ 0x246858f4  0>,
				<DCC_READ 0x246858fc  0>,
				<DCC_READ 0x24685920  0>,
				<DCC_READ 0x24685928  0>,
				<DCC_READ 0x24685944  0>,
				<DCC_READ 0x24686604  0>,
				<DCC_READ 0x2468660c  0>,
				<DCC_READ 0x24687010  0>,
				<DCC_READ 0x246c5804  0>,
				<DCC_READ 0x246c0310  0>,
				<DCC_READ 0x246c0400 2 0>,
				<DCC_READ 0x246c0410 3 0>,
				<DCC_READ 0x246c0428  0>,
				<DCC_READ 0x246c0430  0>,
				<DCC_READ 0x246c0440  0>,
				<DCC_READ 0x246c0448  0>,
				<DCC_READ 0x246c04a0  0>,
				<DCC_READ 0x246c04b0 3 0>,
				<DCC_READ 0x246c04d0 2 0>,
				<DCC_READ 0x246c341c  0>,
				<DCC_READ 0x246c590c  0>,
				<DCC_READ 0x246c5a14  0>,
				<DCC_READ 0x246c5c1c  0>,
				<DCC_READ 0x246c5c38  0>,
				<DCC_READ 0x246c9100  0>,
				<DCC_READ 0x246c9110  0>,
				<DCC_READ 0x246c9120  0>,
				<DCC_READ 0x246c9180 2 0>,
				<DCC_READ 0x246e0618  0>,
				<DCC_READ 0x246e0684  0>,
				<DCC_READ 0x246e068c  0>,
				<DCC_READ 0x24840310  0>,
				<DCC_READ 0x24840400 2 0>,
				<DCC_READ 0x24840410 3 0>,
				<DCC_READ 0x24840428  0>,
				<DCC_READ 0x24840430  0>,
				<DCC_READ 0x24840440  0>,
				<DCC_READ 0x24840448  0>,
				<DCC_READ 0x248404a0  0>,
				<DCC_READ 0x248404b0 3 0>,
				<DCC_READ 0x248404d0 2 0>,
				<DCC_READ 0x2484341c  0>,
				<DCC_READ 0x24845804  0>,
				<DCC_READ 0x2484590c  0>,
				<DCC_READ 0x24845a14  0>,
				<DCC_READ 0x24845c1c  0>,
				<DCC_READ 0x24845c38  0>,
				<DCC_READ 0x24849100  0>,
				<DCC_READ 0x24849110  0>,
				<DCC_READ 0x24849120  0>,
				<DCC_READ 0x24849180 2 0>,
				<DCC_READ 0x24860618  0>,
				<DCC_READ 0x24860684  0>,
				<DCC_READ 0x2486068c  0>,
				<DCC_READ 0x248c0310  0>,
				<DCC_READ 0x248c0400 2 0>,
				<DCC_READ 0x248c0410 3 0>,
				<DCC_READ 0x248c0428  0>,
				<DCC_READ 0x248c0430  0>,
				<DCC_READ 0x248c0440  0>,
				<DCC_READ 0x248c0448  0>,
				<DCC_READ 0x248c04a0  0>,
				<DCC_READ 0x248c04b0 3 0>,
				<DCC_READ 0x248c04d0 2 0>,
				<DCC_READ 0x248c341c  0>,
				<DCC_READ 0x248c5804  0>,
				<DCC_READ 0x248c590c  0>,
				<DCC_READ 0x248c5a14  0>,
				<DCC_READ 0x248c5c1c  0>,
				<DCC_READ 0x248c5c38  0>,
				<DCC_READ 0x248c9100  0>,
				<DCC_READ 0x248c9110  0>,
				<DCC_READ 0x248c9120  0>,
				<DCC_READ 0x248c9180 2 0>,
				<DCC_READ 0x248e0618  0>,
				<DCC_READ 0x248e0684  0>,
				<DCC_READ 0x248e068c  0>,
				<DCC_READ 0x25000004  0>,
				<DCC_READ 0x25001004  0>,
				<DCC_READ 0x25002004  0>,
				<DCC_READ 0x25003004  0>,
				<DCC_READ 0x25004004  0>,
				<DCC_READ 0x25005004  0>,
				<DCC_READ 0x25006004  0>,
				<DCC_READ 0x25007004  0>,
				<DCC_READ 0x25008004  0>,
				<DCC_READ 0x25009004  0>,
				<DCC_READ 0x2500a004  0>,
				<DCC_READ 0x2500b004  0>,
				<DCC_READ 0x2500c004  0>,
				<DCC_READ 0x2500d004  0>,
				<DCC_READ 0x2500e004  0>,
				<DCC_READ 0x2500f004  0>,
				<DCC_READ 0x25010004  0>,
				<DCC_READ 0x25011004  0>,
				<DCC_READ 0x25012004  0>,
				<DCC_READ 0x25013004  0>,
				<DCC_READ 0x25014004  0>,
				<DCC_READ 0x25015004  0>,
				<DCC_READ 0x25016004  0>,
				<DCC_READ 0x25017004  0>,
				<DCC_READ 0x25018004  0>,
				<DCC_READ 0x25019004  0>,
				<DCC_READ 0x2501a004  0>,
				<DCC_READ 0x2501b004  0>,
				<DCC_READ 0x2501c004  0>,
				<DCC_READ 0x2501d004  0>,
				<DCC_READ 0x2501e004  0>,
				<DCC_READ 0x2501f004  0>,
				<DCC_READ 0x25020348  0>,
				<DCC_READ 0x25020480  0>,
				<DCC_READ 0x25022400  0>,
				<DCC_READ 0x25023210  0>,
				<DCC_READ 0x25023220 4 0>,
				<DCC_READ 0x25023258 2 0>,
				<DCC_READ 0x25023308  0>,
				<DCC_READ 0x25023318  0>,
				<DCC_READ 0x25025000  0>,
				<DCC_READ 0x25025010  0>,
				<DCC_READ 0x25038100  0>,
				<DCC_READ 0x2503c030  0>,
				<DCC_READ 0x2504002c 4 0>,
				<DCC_READ 0x25040048 5 0>,
				<DCC_READ 0x25040060 2 0>,
				<DCC_READ 0x25040070 5 0>,
				<DCC_READ 0x25042044 3 0>,
				<DCC_READ 0x250420b0  0>,
				<DCC_READ 0x25042104  0>,
				<DCC_READ 0x25042114  0>,
				<DCC_READ 0x25048004 5 0>,
				<DCC_READ 0x2504c034  0>,
				<DCC_READ 0x25050020  0>,
				<DCC_READ 0x2506004c 8 0>,
				<DCC_READ 0x2507b03c  0>,
				<DCC_READ 0x2507b05c  0>,
				<DCC_READ 0x2507a01c 4 0>,
				<DCC_READ 0x2507a034 4 0>,
				<DCC_READ 0x2507a058  0>,
				<DCC_READ 0x2507a060  0>,
				<DCC_READ 0x2507a068  0>,
				<DCC_READ 0x2507a200  0>,
				<DCC_READ 0x2507b020  0>,
				<DCC_READ 0x2507b030 3 0>,
				<DCC_READ 0x2507b040 7 0>,
				<DCC_READ 0x2507b060 8 0>,
				<DCC_READ 0x2507b084  0>,
				<DCC_READ 0x2507b090 5 0>,
				<DCC_READ 0x2507b18c  0>,
				<DCC_READ 0x2507b1b0  0>,
				<DCC_READ 0x2507b204 13 0>,
				<DCC_READ 0x250a6010  0>,
				<DCC_READ 0x250a002c  0>,
				<DCC_READ 0x250a009c 2 0>,
				<DCC_READ 0x250a00a8 3 0>,
				<DCC_READ 0x250a00b8  0>,
				<DCC_READ 0x250a00c0 2 0>,
				<DCC_READ 0x250a00cc 4 0>,
				<DCC_READ 0x250a00e0  0>,
				<DCC_READ 0x250a00e8  0>,
				<DCC_READ 0x250a00f0  0>,
				<DCC_READ 0x250a00f0  0>,
				<DCC_READ 0x250a0100  0>,
				<DCC_READ 0x250a0108  0>,
				<DCC_READ 0x250a0110  0>,
				<DCC_READ 0x250a0118  0>,
				<DCC_READ 0x250a0120  0>,
				<DCC_READ 0x250a0128  0>,
				<DCC_READ 0x250a1010  0>,
				<DCC_READ 0x250a1070  0>,
				<DCC_READ 0x250a3004  0>,
				<DCC_READ 0x250a6008 2 0>,
				<DCC_READ 0x250a7008 3 0>,
				<DCC_READ 0x250a9004  0>,
				<DCC_READ 0x250a9010 3 0>,
				<DCC_READ 0x250a9020 3 0>,
				<DCC_READ 0x250a9030 3 0>,
				<DCC_READ 0x250a9040 3 0>,
				<DCC_READ 0x250a9050 3 0>,
				<DCC_READ 0x250aa004  0>,
				<DCC_READ 0x250aa010 3 0>,
				<DCC_READ 0x250aa020 3 0>,
				<DCC_READ 0x250aa030 3 0>,
				<DCC_READ 0x250aa040 3 0>,
				<DCC_READ 0x250aa050 3 0>,
				<DCC_READ 0x250b001c  0>,
				<DCC_READ 0x250b101c  0>,
				<DCC_READ 0x250b201c  0>,
				<DCC_READ 0x250b301c  0>,
				<DCC_READ 0x250b401c  0>,
				<DCC_READ 0x250b501c  0>,
				<DCC_READ 0x250b601c  0>,
				<DCC_READ 0x250b701c  0>,
				<DCC_READ 0x250b801c  0>,
				<DCC_READ 0x250b901c  0>,
				<DCC_READ 0x250ba01c  0>,
				<DCC_READ 0x250bb01c  0>,
				<DCC_READ 0x250bc01c  0>,
				<DCC_READ 0x250bd01c  0>,
				<DCC_READ 0x250be01c  0>,
				<DCC_READ 0x250bf01c  0>,
				<DCC_READ 0x25200004  0>,
				<DCC_READ 0x25201004  0>,
				<DCC_READ 0x25202004  0>,
				<DCC_READ 0x25203004  0>,
				<DCC_READ 0x25204004  0>,
				<DCC_READ 0x25205004  0>,
				<DCC_READ 0x25206004  0>,
				<DCC_READ 0x25207004  0>,
				<DCC_READ 0x25208004  0>,
				<DCC_READ 0x25209004  0>,
				<DCC_READ 0x2520a004  0>,
				<DCC_READ 0x2520b004  0>,
				<DCC_READ 0x2520c004  0>,
				<DCC_READ 0x2520d004  0>,
				<DCC_READ 0x2520e004  0>,
				<DCC_READ 0x2520f004  0>,
				<DCC_READ 0x25210004  0>,
				<DCC_READ 0x25211004  0>,
				<DCC_READ 0x25212004  0>,
				<DCC_READ 0x25213004  0>,
				<DCC_READ 0x25214004  0>,
				<DCC_READ 0x25215004  0>,
				<DCC_READ 0x25216004  0>,
				<DCC_READ 0x25217004  0>,
				<DCC_READ 0x25218004  0>,
				<DCC_READ 0x25219004  0>,
				<DCC_READ 0x2521a004  0>,
				<DCC_READ 0x2521b004  0>,
				<DCC_READ 0x2521c004  0>,
				<DCC_READ 0x2521d004  0>,
				<DCC_READ 0x2521e004  0>,
				<DCC_READ 0x2521f004  0>,
				<DCC_READ 0x25220348  0>,
				<DCC_READ 0x25220480  0>,
				<DCC_READ 0x25222400  0>,
				<DCC_READ 0x25223210  0>,
				<DCC_READ 0x25223220 4 0>,
				<DCC_READ 0x25223258 2 0>,
				<DCC_READ 0x25223308  0>,
				<DCC_READ 0x25223318  0>,
				<DCC_READ 0x25225000  0>,
				<DCC_READ 0x25225010  0>,
				<DCC_READ 0x25238100  0>,
				<DCC_READ 0x2523c030  0>,
				<DCC_READ 0x2524002c 4 0>,
				<DCC_READ 0x25240048 5 0>,
				<DCC_READ 0x25240060 2 0>,
				<DCC_READ 0x25240070 5 0>,
				<DCC_READ 0x25242044 3 0>,
				<DCC_READ 0x252420b0  0>,
				<DCC_READ 0x25242104  0>,
				<DCC_READ 0x25242114  0>,
				<DCC_READ 0x25248004 5 0>,
				<DCC_READ 0x2524c034  0>,
				<DCC_READ 0x25250020  0>,
				<DCC_READ 0x2526004c 8 0>,
				<DCC_READ 0x2527b03c  0>,
				<DCC_READ 0x2527b05c  0>,
				<DCC_READ 0x2527a01c 4 0>,
				<DCC_READ 0x2527a034 4 0>,
				<DCC_READ 0x2527a058  0>,
				<DCC_READ 0x2527a060  0>,
				<DCC_READ 0x2527a068  0>,
				<DCC_READ 0x2527a200  0>,
				<DCC_READ 0x2527b020  0>,
				<DCC_READ 0x2527b030 3 0>,
				<DCC_READ 0x2527b040 7 0>,
				<DCC_READ 0x2527b060 8 0>,
				<DCC_READ 0x2527b084  0>,
				<DCC_READ 0x2527b090 5 0>,
				<DCC_READ 0x2527b18c  0>,
				<DCC_READ 0x2527b1b0  0>,
				<DCC_READ 0x2527b204 13 0>,
				<DCC_READ 0x252a002c  0>,
				<DCC_READ 0x252a009c 2 0>,
				<DCC_READ 0x252a00a8 3 0>,
				<DCC_READ 0x252a00b8  0>,
				<DCC_READ 0x252a00c0 2 0>,
				<DCC_READ 0x252a00cc 4 0>,
				<DCC_READ 0x252a00e0  0>,
				<DCC_READ 0x252a00e8  0>,
				<DCC_READ 0x252a00f0  0>,
				<DCC_READ 0x252a00f0  0>,
				<DCC_READ 0x252a0100  0>,
				<DCC_READ 0x252a0108  0>,
				<DCC_READ 0x252a0110  0>,
				<DCC_READ 0x252a0118  0>,
				<DCC_READ 0x252a0120  0>,
				<DCC_READ 0x252a0128  0>,
				<DCC_READ 0x252a1010  0>,
				<DCC_READ 0x252a1070  0>,
				<DCC_READ 0x252a3004  0>,
				<DCC_READ 0x252a6008 3 0>,
				<DCC_READ 0x252a7008 3 0>,
				<DCC_READ 0x252a9004  0>,
				<DCC_READ 0x252a9010 3 0>,
				<DCC_READ 0x252a9020 3 0>,
				<DCC_READ 0x252a9030 3 0>,
				<DCC_READ 0x252a9040 3 0>,
				<DCC_READ 0x252a9050 3 0>,
				<DCC_READ 0x252aa004  0>,
				<DCC_READ 0x252aa010 3 0>,
				<DCC_READ 0x252aa020 3 0>,
				<DCC_READ 0x252aa030 3 0>,
				<DCC_READ 0x252aa040 3 0>,
				<DCC_READ 0x252aa050 3 0>,
				<DCC_READ 0x252b001c  0>,
				<DCC_READ 0x252b101c  0>,
				<DCC_READ 0x252b201c  0>,
				<DCC_READ 0x252b301c  0>,
				<DCC_READ 0x252b401c  0>,
				<DCC_READ 0x252b501c  0>,
				<DCC_READ 0x252b601c  0>,
				<DCC_READ 0x252b701c  0>,
				<DCC_READ 0x252b801c  0>,
				<DCC_READ 0x252b901c  0>,
				<DCC_READ 0x252ba01c  0>,
				<DCC_READ 0x252bb01c  0>,
				<DCC_READ 0x252bc01c  0>,
				<DCC_READ 0x252bd01c  0>,
				<DCC_READ 0x252be01c  0>,
				<DCC_READ 0x252bf01c  0>,
				<DCC_READ 0x25400004  0>,
				<DCC_READ 0x25401004  0>,
				<DCC_READ 0x25402004  0>,
				<DCC_READ 0x25403004  0>,
				<DCC_READ 0x25404004  0>,
				<DCC_READ 0x25405004  0>,
				<DCC_READ 0x25406004  0>,
				<DCC_READ 0x25407004  0>,
				<DCC_READ 0x25408004  0>,
				<DCC_READ 0x25409004  0>,
				<DCC_READ 0x2540a004  0>,
				<DCC_READ 0x2540b004  0>,
				<DCC_READ 0x2540c004  0>,
				<DCC_READ 0x2540d004  0>,
				<DCC_READ 0x2540e004  0>,
				<DCC_READ 0x2540f004  0>,
				<DCC_READ 0x25410004  0>,
				<DCC_READ 0x25411004  0>,
				<DCC_READ 0x25412004  0>,
				<DCC_READ 0x25413004  0>,
				<DCC_READ 0x25414004  0>,
				<DCC_READ 0x25415004  0>,
				<DCC_READ 0x25416004  0>,
				<DCC_READ 0x25417004  0>,
				<DCC_READ 0x25418004  0>,
				<DCC_READ 0x25419004  0>,
				<DCC_READ 0x2541a004  0>,
				<DCC_READ 0x2541b004  0>,
				<DCC_READ 0x2541c004  0>,
				<DCC_READ 0x2541d004  0>,
				<DCC_READ 0x2541e004  0>,
				<DCC_READ 0x2541f004  0>,
				<DCC_READ 0x25420348  0>,
				<DCC_READ 0x25420480  0>,
				<DCC_READ 0x25422400  0>,
				<DCC_READ 0x25423210  0>,
				<DCC_READ 0x25423220 4 0>,
				<DCC_READ 0x25423258 2 0>,
				<DCC_READ 0x25423308  0>,
				<DCC_READ 0x25423318  0>,
				<DCC_READ 0x25425000  0>,
				<DCC_READ 0x25425010  0>,
				<DCC_READ 0x25438100  0>,
				<DCC_READ 0x2543c030  0>,
				<DCC_READ 0x2544002c 4 0>,
				<DCC_READ 0x25440048 5 0>,
				<DCC_READ 0x25440060 2 0>,
				<DCC_READ 0x25440070 5 0>,
				<DCC_READ 0x25442044 3 0>,
				<DCC_READ 0x254420b0  0>,
				<DCC_READ 0x25442104  0>,
				<DCC_READ 0x25442114  0>,
				<DCC_READ 0x25448004 5 0>,
				<DCC_READ 0x2544c034  0>,
				<DCC_READ 0x25450020  0>,
				<DCC_READ 0x2546004c 8 0>,
				<DCC_READ 0x2547b03c  0>,
				<DCC_READ 0x2547b05c  0>,
				<DCC_READ 0x2547a01c 4 0>,
				<DCC_READ 0x2547a034 4 0>,
				<DCC_READ 0x2547a058  0>,
				<DCC_READ 0x2547a060  0>,
				<DCC_READ 0x2547a068  0>,
				<DCC_READ 0x2547a200  0>,
				<DCC_READ 0x2547b020  0>,
				<DCC_READ 0x2547b030 3 0>,
				<DCC_READ 0x2547b040 7 0>,
				<DCC_READ 0x2547b060 8 0>,
				<DCC_READ 0x2547b084  0>,
				<DCC_READ 0x2547b090 5 0>,
				<DCC_READ 0x2547b18c  0>,
				<DCC_READ 0x2547b1b0  0>,
				<DCC_READ 0x2547b204 13 0>,
				<DCC_READ 0x254a002c  0>,
				<DCC_READ 0x254a009c 2 0>,
				<DCC_READ 0x254a00a8 3 0>,
				<DCC_READ 0x254a00b8  0>,
				<DCC_READ 0x254a00c0 2 0>,
				<DCC_READ 0x254a00cc 4 0>,
				<DCC_READ 0x254a00e0  0>,
				<DCC_READ 0x254a00e8  0>,
				<DCC_READ 0x254a00f0  0>,
				<DCC_READ 0x254a00f0  0>,
				<DCC_READ 0x254a0100  0>,
				<DCC_READ 0x254a0108  0>,
				<DCC_READ 0x254a0110  0>,
				<DCC_READ 0x254a0118  0>,
				<DCC_READ 0x254a0120  0>,
				<DCC_READ 0x254a0128  0>,
				<DCC_READ 0x254a1010  0>,
				<DCC_READ 0x254a1070  0>,
				<DCC_READ 0x254a3004  0>,
				<DCC_READ 0x254a6008 3 0>,
				<DCC_READ 0x254a7008 3 0>,
				<DCC_READ 0x254a9004  0>,
				<DCC_READ 0x254a9010 3 0>,
				<DCC_READ 0x254a9020 3 0>,
				<DCC_READ 0x254a9030 3 0>,
				<DCC_READ 0x254a9040 3 0>,
				<DCC_READ 0x254a9050 3 0>,
				<DCC_READ 0x254aa004  0>,
				<DCC_READ 0x254aa010 3 0>,
				<DCC_READ 0x254aa020 3 0>,
				<DCC_READ 0x254aa030 3 0>,
				<DCC_READ 0x254aa040 3 0>,
				<DCC_READ 0x254aa050 3 0>,
				<DCC_READ 0x254b001c  0>,
				<DCC_READ 0x254b101c  0>,
				<DCC_READ 0x254b201c  0>,
				<DCC_READ 0x254b301c  0>,
				<DCC_READ 0x254b401c  0>,
				<DCC_READ 0x254b501c  0>,
				<DCC_READ 0x254b601c  0>,
				<DCC_READ 0x254b701c  0>,
				<DCC_READ 0x254b801c  0>,
				<DCC_READ 0x254b901c  0>,
				<DCC_READ 0x254ba01c  0>,
				<DCC_READ 0x254bb01c  0>,
				<DCC_READ 0x254bc01c  0>,
				<DCC_READ 0x254bd01c  0>,
				<DCC_READ 0x254be01c  0>,
				<DCC_READ 0x254bf01c  0>,
				<DCC_READ 0x25600004  0>,
				<DCC_READ 0x25601004  0>,
				<DCC_READ 0x25602004  0>,
				<DCC_READ 0x25603004  0>,
				<DCC_READ 0x25604004  0>,
				<DCC_READ 0x25605004  0>,
				<DCC_READ 0x25606004  0>,
				<DCC_READ 0x25607004  0>,
				<DCC_READ 0x25608004  0>,
				<DCC_READ 0x25609004  0>,
				<DCC_READ 0x2560a004  0>,
				<DCC_READ 0x2560b004  0>,
				<DCC_READ 0x2560c004  0>,
				<DCC_READ 0x2560d004  0>,
				<DCC_READ 0x2560e004  0>,
				<DCC_READ 0x2560f004  0>,
				<DCC_READ 0x25610004  0>,
				<DCC_READ 0x25611004  0>,
				<DCC_READ 0x25612004  0>,
				<DCC_READ 0x25613004  0>,
				<DCC_READ 0x25614004  0>,
				<DCC_READ 0x25615004  0>,
				<DCC_READ 0x25616004  0>,
				<DCC_READ 0x25617004  0>,
				<DCC_READ 0x25618004  0>,
				<DCC_READ 0x25619004  0>,
				<DCC_READ 0x2561a004  0>,
				<DCC_READ 0x2561b004  0>,
				<DCC_READ 0x2561c004  0>,
				<DCC_READ 0x2561d004  0>,
				<DCC_READ 0x2561e004  0>,
				<DCC_READ 0x2561f004  0>,
				<DCC_READ 0x25620348  0>,
				<DCC_READ 0x25620480  0>,
				<DCC_READ 0x25622400  0>,
				<DCC_READ 0x25623210  0>,
				<DCC_READ 0x25623220 4 0>,
				<DCC_READ 0x25623258 2 0>,
				<DCC_READ 0x25623308  0>,
				<DCC_READ 0x25623318  0>,
				<DCC_READ 0x25625000  0>,
				<DCC_READ 0x25625010  0>,
				<DCC_READ 0x25638100  0>,
				<DCC_READ 0x2563c030  0>,
				<DCC_READ 0x2564002c 4 0>,
				<DCC_READ 0x25640048 5 0>,
				<DCC_READ 0x25640060 2 0>,
				<DCC_READ 0x25640070 5 0>,
				<DCC_READ 0x25642044 3 0>,
				<DCC_READ 0x256420b0  0>,
				<DCC_READ 0x25642104  0>,
				<DCC_READ 0x25642114  0>,
				<DCC_READ 0x25648004 5 0>,
				<DCC_READ 0x2564c034  0>,
				<DCC_READ 0x25650020  0>,
				<DCC_READ 0x2566004c 8 0>,
				<DCC_READ 0x2567b03c  0>,
				<DCC_READ 0x2567b05c  0>,
				<DCC_READ 0x2567a01c 4 0>,
				<DCC_READ 0x2567a034 4 0>,
				<DCC_READ 0x2567a058  0>,
				<DCC_READ 0x2567a060  0>,
				<DCC_READ 0x2567a068  0>,
				<DCC_READ 0x2567a200  0>,
				<DCC_READ 0x2567b020  0>,
				<DCC_READ 0x2567b030 3 0>,
				<DCC_READ 0x2567b040 7 0>,
				<DCC_READ 0x2567b060 8 0>,
				<DCC_READ 0x2567b084  0>,
				<DCC_READ 0x2567b090 5 0>,
				<DCC_READ 0x2567b18c  0>,
				<DCC_READ 0x2567b1b0  0>,
				<DCC_READ 0x2567b204 13 0>,
				<DCC_READ 0x256a002c  0>,
				<DCC_READ 0x256a009c 2 0>,
				<DCC_READ 0x256a00a8 3 0>,
				<DCC_READ 0x256a00b8  0>,
				<DCC_READ 0x256a00c0 2 0>,
				<DCC_READ 0x256a00cc 4 0>,
				<DCC_READ 0x256a00e0  0>,
				<DCC_READ 0x256a00e8  0>,
				<DCC_READ 0x256a00f0  0>,
				<DCC_READ 0x256a00f0  0>,
				<DCC_READ 0x256a0100  0>,
				<DCC_READ 0x256a0108  0>,
				<DCC_READ 0x256a0110  0>,
				<DCC_READ 0x256a0118  0>,
				<DCC_READ 0x256a0120  0>,
				<DCC_READ 0x256a0128  0>,
				<DCC_READ 0x256a1010  0>,
				<DCC_READ 0x256a1070  0>,
				<DCC_READ 0x256a3004  0>,
				<DCC_READ 0x256a6008 3 0>,
				<DCC_READ 0x256a7008 3 0>,
				<DCC_READ 0x256a9004  0>,
				<DCC_READ 0x256a9010 3 0>,
				<DCC_READ 0x256a9020 3 0>,
				<DCC_READ 0x256a9030 3 0>,
				<DCC_READ 0x256a9040 3 0>,
				<DCC_READ 0x256a9050 3 0>,
				<DCC_READ 0x256aa004  0>,
				<DCC_READ 0x256aa010 3 0>,
				<DCC_READ 0x256aa020 3 0>,
				<DCC_READ 0x256aa030 3 0>,
				<DCC_READ 0x256aa040 3 0>,
				<DCC_READ 0x256aa050 3 0>,
				<DCC_READ 0x256b001c  0>,
				<DCC_READ 0x256b101c  0>,
				<DCC_READ 0x256b201c  0>,
				<DCC_READ 0x256b301c  0>,
				<DCC_READ 0x256b401c  0>,
				<DCC_READ 0x256b501c  0>,
				<DCC_READ 0x256b601c  0>,
				<DCC_READ 0x256b701c  0>,
				<DCC_READ 0x256b801c  0>,
				<DCC_READ 0x256b901c  0>,
				<DCC_READ 0x256ba01c  0>,
				<DCC_READ 0x256bb01c  0>,
				<DCC_READ 0x256bc01c  0>,
				<DCC_READ 0x256bd01c  0>,
				<DCC_READ 0x256be01c  0>,
				<DCC_READ 0x256bf01c  0>,
				<DCC_READ 0x25820348  0>,
				<DCC_READ 0x25820480  0>,
				<DCC_READ 0x25822400  0>,
				<DCC_READ 0x25823220 4 0>,
				<DCC_READ 0x25823258 2 0>,
				<DCC_READ 0x25823308  0>,
				<DCC_READ 0x25823318  0>,
				<DCC_READ 0x25838100  0>,
				<DCC_READ 0x2583c030  0>,
				<DCC_READ 0x25842044 3 0>,
				<DCC_READ 0x258420b0  0>,
				<DCC_READ 0x25842104  0>,
				<DCC_READ 0x25842114  0>,
				<DCC_READ 0x25848004 5 0>,
				<DCC_READ 0x2584c034  0>,
				<DCC_READ 0x25850020  0>,
				<DCC_READ 0x2586004c 8 0>,
				<DCC_READ 0x258a4040 48 0>,
				<DCC_READ 0x258b0000  0>,
				<DCC_READ 0x258b005c  0>,
				<DCC_READ 0x258b1000  0>,
				<DCC_READ 0x258b105c  0>,
				<DCC_READ 0x258b2000  0>,
				<DCC_READ 0x258b205c  0>,
				<DCC_READ 0x258b3000  0>,
				<DCC_READ 0x258b305c  0>,
				<DCC_READ 0x258b4000  0>,
				<DCC_READ 0x258b405c  0>,
				<DCC_READ 0x258b5000  0>,
				<DCC_READ 0x258b505c  0>,
				<DCC_READ 0x258b6000  0>,
				<DCC_READ 0x258b605c  0>,
				<DCC_READ 0x258b7000  0>,
				<DCC_READ 0x258b705c  0>,
				<DCC_READ 0x258b8000  0>,
				<DCC_READ 0x258b805c  0>,
				<DCC_READ 0x258b9000  0>,
				<DCC_READ 0x258b905c  0>,
				<DCC_READ 0x258ba000  0>,
				<DCC_READ 0x258ba05c  0>,
				<DCC_READ 0x258bb000  0>,
				<DCC_READ 0x258bb05c  0>,
				<DCC_READ 0x258bc000  0>,
				<DCC_READ 0x258bc05c  0>,
				<DCC_READ 0x258bd000  0>,
				<DCC_READ 0x258bd05c  0>,
				<DCC_READ 0x258be000  0>,
				<DCC_READ 0x258be05c  0>,
				<DCC_READ 0x258bf000  0>,
				<DCC_READ 0x258bf05c  0>,
				<DCC_READ 0x25a00004  0>,
				<DCC_READ 0x25a01004  0>,
				<DCC_READ 0x25a02004  0>,
				<DCC_READ 0x25a03004  0>,
				<DCC_READ 0x25a04004  0>,
				<DCC_READ 0x25a05004  0>,
				<DCC_READ 0x25a06004  0>,
				<DCC_READ 0x25a07004  0>,
				<DCC_READ 0x25a08004  0>,
				<DCC_READ 0x25a09004  0>,
				<DCC_READ 0x25a0a004  0>,
				<DCC_READ 0x25a0b004  0>,
				<DCC_READ 0x25a0c004  0>,
				<DCC_READ 0x25a0d004  0>,
				<DCC_READ 0x25a0e004  0>,
				<DCC_READ 0x25a0f004  0>,
				<DCC_READ 0x25a10004  0>,
				<DCC_READ 0x25a11004  0>,
				<DCC_READ 0x25a12004  0>,
				<DCC_READ 0x25a13004  0>,
				<DCC_READ 0x25a14004  0>,
				<DCC_READ 0x25a15004  0>,
				<DCC_READ 0x25a16004  0>,
				<DCC_READ 0x25a17004  0>,
				<DCC_READ 0x25a18004  0>,
				<DCC_READ 0x25a19004  0>,
				<DCC_READ 0x25a1a004  0>,
				<DCC_READ 0x25a1b004  0>,
				<DCC_READ 0x25a1c004  0>,
				<DCC_READ 0x25a1d004  0>,
				<DCC_READ 0x25a1e004  0>,
				<DCC_READ 0x25a1f004  0>,
				<DCC_READ 0x25a20348  0>,
				<DCC_READ 0x25a20480  0>,
				<DCC_READ 0x25a22400  0>,
				<DCC_READ 0x25a23220 4 0>,
				<DCC_READ 0x25a23258 2 0>,
				<DCC_READ 0x25a23308  0>,
				<DCC_READ 0x25a23318  0>,
				<DCC_READ 0x25a38100  0>,
				<DCC_READ 0x25a3c030  0>,
				<DCC_READ 0x25a42044 3 0>,
				<DCC_READ 0x25a420b0  0>,
				<DCC_READ 0x25a42104  0>,
				<DCC_READ 0x25a42114  0>,
				<DCC_READ 0x25a48004 5 0>,
				<DCC_READ 0x25a4c034  0>,
				<DCC_READ 0x25a50020  0>,
				<DCC_READ 0x25a6004c 8 0>,
				<DCC_READ 0x2503400c  0>,
				<DCC_READ 0x25821004  0>,
				<DCC_READ 0x2582100c  0>,
				<DCC_READ 0x25821014  0>,
				<DCC_READ 0x2582101c  0>,
				<DCC_READ 0x25821024  0>,
				<DCC_READ 0x2582102c  0>,
				<DCC_READ 0x25821034  0>,
				<DCC_READ 0x2582103c  0>,
				<DCC_READ 0x25821044  0>,
				<DCC_READ 0x2582104c  0>,
				<DCC_READ 0x25821054  0>,
				<DCC_READ 0x2582105c  0>,
				<DCC_READ 0x25821064  0>,
				<DCC_READ 0x2582106c  0>,
				<DCC_READ 0x25821074  0>,
				<DCC_READ 0x2582107c  0>,
				<DCC_READ 0x25821084  0>,
				<DCC_READ 0x2582108c  0>,
				<DCC_READ 0x25821094  0>,
				<DCC_READ 0x2582109c  0>,
				<DCC_READ 0x258210a4  0>,
				<DCC_READ 0x258210ac  0>,
				<DCC_READ 0x258210b4  0>,
				<DCC_READ 0x258210bc  0>,
				<DCC_READ 0x258210c4  0>,
				<DCC_READ 0x258210cc  0>,
				<DCC_READ 0x258210d4  0>,
				<DCC_READ 0x258210dc  0>,
				<DCC_READ 0x258210e4  0>,
				<DCC_READ 0x258210ec  0>,
				<DCC_READ 0x258210f4  0>,
				<DCC_READ 0x258210fc  0>,
				<DCC_READ 0x24102008  0>,
				<DCC_READ 0x24102010  0>,
				<DCC_READ 0x24102018  0>,
				<DCC_READ 0x24102020 6 0>,
				<DCC_READ 0x24102408  0>,
				<DCC_READ 0x24102410  0>,
				<DCC_READ 0x24102418  0>,
				<DCC_READ 0x24102420 6 0>,
				<DCC_READ 0x24142008  0>,
				<DCC_READ 0x24142010  0>,
				<DCC_READ 0x24142018  0>,
				<DCC_READ 0x24142020 6 0>,
				<DCC_READ 0x24142408  0>,
				<DCC_READ 0x24142410  0>,
				<DCC_READ 0x24142418  0>,
				<DCC_READ 0x24142420 6 0>,
				<DCC_READ 0x24182008  0>,
				<DCC_READ 0x24182010  0>,
				<DCC_READ 0x24182018  0>,
				<DCC_READ 0x24182020 6 0>,
				<DCC_READ 0x24182408  0>,
				<DCC_READ 0x24182410  0>,
				<DCC_READ 0x24182418  0>,
				<DCC_READ 0x24182420 6 0>,
				<DCC_READ 0x24100808 2 0>,
				<DCC_READ 0x24100c08 2 0>,
				<DCC_READ 0x24140808 2 0>,
				<DCC_READ 0x24140c08 2 0>,
				<DCC_READ 0x24180008 2 0>,
				<DCC_READ 0x24180408 2 0>,
				<DCC_READ 0x24183048 1 0>,
				<DCC_READ 0x24101008 1 0>,
				<DCC_LOOP 0x4  0 0>,
				<DCC_READ 0x24101010 2 0>,
				<DCC_LOOP 0x1  0 0>,
				<DCC_READ 0x24101018 1 0>,
				<DCC_READ 0x24141008 1 0>,
				<DCC_LOOP 0x4  0 0>,
				<DCC_READ 0x24141010 2 0>,
				<DCC_LOOP 0x1  0 0>,
				<DCC_READ 0x24141018 1 0>,
				<DCC_READ 0x24181008 1 0>,
				<DCC_LOOP 0x3  0 0>,
				<DCC_READ 0x24181010 2 0>,
				<DCC_LOOP 0x1  0 0>,
				<DCC_READ 0x24181018 1 0>,
				<DCC_READ 0x24100810 1 0>,
				<DCC_LOOP 0x40  0 0>,
				<DCC_READ 0x24100838 1 0>,
				<DCC_READ 0x24100830 2 0>,
				<DCC_READ 0x24100830 2 0>,
				<DCC_READ 0x24100830 2 0>,
				<DCC_READ 0x24100830 2 0>,
				<DCC_LOOP 0x1  0 0>,
				<DCC_READ 0x24100c10 1 0>,
				<DCC_LOOP 0x40  0 0>,
				<DCC_READ 0x24100c38 1 0>,
				<DCC_READ 0x24100c30 2 0>,
				<DCC_READ 0x24100c30 2 0>,
				<DCC_READ 0x24100c30 2 0>,
				<DCC_READ 0x24100c30 2 0>,
				<DCC_LOOP 0x1  0 0>,
				<DCC_READ 0x24140810 1 0>,
				<DCC_LOOP 0x40  0 0>,
				<DCC_READ 0x24140838 1 0>,
				<DCC_READ 0x24140830 2 0>,
				<DCC_READ 0x24140830 2 0>,
				<DCC_READ 0x24140830 2 0>,
				<DCC_READ 0x24140830 2 0>,
				<DCC_LOOP 0x1  0 0>,
				<DCC_READ 0x24140c10 1 0>,
				<DCC_LOOP 0x40  0 0>,
				<DCC_READ 0x24140c38 1 0>,
				<DCC_READ 0x24140c30 2 0>,
				<DCC_READ 0x24140c30 2 0>,
				<DCC_READ 0x24140c30 2 0>,
				<DCC_READ 0x24140c30 2 0>,
				<DCC_LOOP 0x1  0 0>,
				<DCC_READ 0x24180010 1 0>,
				<DCC_LOOP 0x10  0 0>,
				<DCC_READ 0x24180038 1 0>,
				<DCC_READ 0x24180030 2 0>,
				<DCC_READ 0x24180030 2 0>,
				<DCC_READ 0x24180030 2 0>,
				<DCC_READ 0x24180030 2 0>,
				<DCC_LOOP 0x1  0 0>,
				<DCC_READ 0x24180410 1 0>,
				<DCC_LOOP 0x10  0 0>,
				<DCC_READ 0x24180438 1 0>,
				<DCC_READ 0x24180430 2 0>,
				<DCC_READ 0x24180430 2 0>,
				<DCC_READ 0x24180430 2 0>,
				<DCC_READ 0x24180430 2 0>,
				<DCC_LOOP 0x1  0 0>,
				<DCC_READ 0x24131010  0>,
				<DCC_READ 0x24133010  0>,
				<DCC_READ 0x24135010  0>,
				<DCC_READ 0x24137010  0>,
				<DCC_READ 0x24138010  0>,
				<DCC_READ 0x24139010  0>,
				<DCC_READ 0x24171010  0>,
				<DCC_READ 0x24173010  0>,
				<DCC_READ 0x24175010  0>,
				<DCC_READ 0x24177010  0>,
				<DCC_READ 0x24178010  0>,
				<DCC_READ 0x24179010  0>,
				<DCC_READ 0x241b5010  0>,
				<DCC_READ 0x241b7010  0>,
				<DCC_READ 0x241b9010  0>,
				<DCC_READ 0x241bb010  0>,
				<DCC_READ 0x241bc010  0>,
				<DCC_READ 0x241bd010  0>,
				<DCC_READ 0x241bf010  0>,
				<DCC_READ 0x241c1010  0>,
				<DCC_READ 0x16e0008  0>,
				<DCC_READ 0x16e0010  0>,
				<DCC_READ 0x16e0018  0>,
				<DCC_READ 0x16e0020 8 0>,
				<DCC_READ 0x16e0248  0>,
				<DCC_READ 0x16e1008 1 0>,
				<DCC_LOOP 0x3 0 0>,
				<DCC_READ 0x16e1010 2 0>,
				<DCC_LOOP 0x1 0 0>,
				<DCC_READ 0x16e1018 1 0>,
				<DCC_READ 0x16e1088 1 0>,
				<DCC_LOOP 0x3 0 0>,
				<DCC_READ 0x16e1090 2 0>,
				<DCC_LOOP 0x1 0 0>,
				<DCC_READ 0x16e1098 1 0>,
				<DCC_READ 0x16e1108 1 0>,
				<DCC_LOOP 0x7 0 0>,
				<DCC_READ 0x16e1110 2 0>,
				<DCC_LOOP 0x1 0 0>,
				<DCC_READ 0x16e1118 1 0>,
				<DCC_READ 0x16e3088 1 0>,
				<DCC_LOOP 0x2 0 0>,
				<DCC_READ 0x16e3090 2 0>,
				<DCC_LOOP 0x1 0 0>,
				<DCC_READ 0x16e3098 1 0>,
				<DCC_READ 0x16ee010  0>,
				<DCC_READ 0x16ef010  0>,
				<DCC_READ 0x16f0010  0>,
				<DCC_READ 0x16f2010  0>,
				<DCC_READ 0x16f3010  0>,
				<DCC_READ 0x1700008  0>,
				<DCC_READ 0x1700010  0>,
				<DCC_READ 0x1700018  0>,
				<DCC_READ 0x1700020 8 0>,
				<DCC_READ 0x1700240  0>,
				<DCC_READ 0x1700248  0>,
				<DCC_READ 0x1713010  0>,
				<DCC_READ 0x1714010  0>,
				<DCC_READ 0x1715010  0>,
				<DCC_READ 0x1716010  0>,
				<DCC_READ 0x1717010  0>,
				<DCC_READ 0x1718010  0>,
				<DCC_READ 0x171a010  0>,
				<DCC_READ 0x1701008 1 0>,
				<DCC_LOOP 0x6 0 0>,
				<DCC_READ 0x1701010 2 0>,
				<DCC_LOOP 0x1 0 0>,
				<DCC_READ 0x1701018 1 0>,
				<DCC_READ 0x16c0008  0>,
				<DCC_READ 0x16c0010  0>,
				<DCC_READ 0x16c0018  0>,
				<DCC_READ 0x16c0020 8 0>,
				<DCC_READ 0x16c0240  0>,
				<DCC_READ 0x16c0248  0>,
				<DCC_READ 0x16cc010  0>,
				<DCC_READ 0x16cd010  0>,
				<DCC_READ 0x16ce010  0>,
				<DCC_READ 0x16c2008  0>,
				<DCC_LOOP 0x5 0 0>,
				<DCC_READ 0x16c2010 2 0>,
				<DCC_LOOP 0x1 0 0>,
				<DCC_READ 0x16c2018  0>,
				<DCC_READ 0x16c3008  0>,
				<DCC_LOOP 0x4 0 0>,
				<DCC_READ 0x16c3010 2 0>,
				<DCC_LOOP 0x1 0 0>,
				<DCC_READ 0x16c3018  0>,
				<DCC_READ 0x1600008  0>,
				<DCC_READ 0x1600010  0>,
				<DCC_READ 0x1600018  0>,
				<DCC_READ 0x1600020 8 0>,
				<DCC_READ 0x1600240 5 0>,
				<DCC_READ 0x1600258  0>,
				<DCC_READ 0x1602008  0>,
				<DCC_LOOP 0x8 0 0>,
				<DCC_READ 0x1602010 2 0>,
				<DCC_LOOP 0x1 0 0>,
				<DCC_READ 0x1602018  0>,
				<DCC_READ 0x1602088  0>,
				<DCC_LOOP 0x3 0 0>,
				<DCC_READ 0x1602090 2 0>,
				<DCC_LOOP 0x1 0 0>,
				<DCC_READ 0x1602098  0>,
				<DCC_READ 0x1602108  0>,
				<DCC_LOOP 0x3 0 0>,
				<DCC_READ 0x1602110 2 0>,
				<DCC_LOOP 0x1 0 0>,
				<DCC_READ 0x1602118  0>,
				<DCC_READ 0x1602188  0>,
				<DCC_LOOP 0x2 0 0>,
				<DCC_READ 0x1602190 2 0>,
				<DCC_LOOP 0x1 0 0>,
				<DCC_READ 0x1602198  0>,
				<DCC_READ 0x1602208  0>,
				<DCC_LOOP 0x3 0 0>,
				<DCC_READ 0x1602210 2 0>,
				<DCC_LOOP 0x1 0 0>,
				<DCC_READ 0x1602218  0>,
				<DCC_READ 0x1500008  0>,
				<DCC_READ 0x1500010  0>,
				<DCC_READ 0x1500018  0>,
				<DCC_READ 0x1500020 8 0>,
				<DCC_READ 0x1500240  0>,
				<DCC_READ 0x1500248  0>,
				<DCC_READ 0x1500440 4 0>,
				<DCC_READ 0x1502008  0>,
				<DCC_LOOP 0xb 0 0>,
				<DCC_READ 0x1502010 2 >,
				<DCC_LOOP 0x1 0 0>,
				<DCC_READ 0x1502018  0>,
				<DCC_READ 0x1502088  0>,
				<DCC_LOOP 0x4 0 0>,
				<DCC_READ 0x1502090 2 >,
				<DCC_LOOP 0x1 0 0>,
				<DCC_READ 0x1502098  0>,
				<DCC_READ 0x1502108  0>,
				<DCC_LOOP 0x3 0 0>,
				<DCC_READ 0x1502110 2 0>,
				<DCC_LOOP 0x1 0 0>,
				<DCC_READ 0x1502118  0>,
				<DCC_READ 0x1680008  0>,
				<DCC_READ 0x1680010  0>,
				<DCC_READ 0x1680018  0>,
				<DCC_READ 0x1680020 8 0>,
				<DCC_READ 0x1681040  0>,
				<DCC_READ 0x1681048  0>,
				<DCC_READ 0x1690010  0>,
				<DCC_READ 0x169c010  0>,
				<DCC_READ 0x169d010  0>,
				<DCC_READ 0x1682008  0>,
				<DCC_LOOP 0x5 0 0>,
				<DCC_READ 0x1682010 2 0>,
				<DCC_LOOP 0x1 0 0>,
				<DCC_READ 0x1682018  0>,
				<DCC_READ 0x240e0008  0>,
				<DCC_READ 0x240e0010  0>,
				<DCC_READ 0x240e0018  0>,
				<DCC_READ 0x240e0020 8 0>,
				<DCC_READ 0x240e0240  0>,
				<DCC_READ 0x240e0248  0>,
				<DCC_READ 0x240e1000 3 0>,
				<DCC_LOOP 0x8 0 0>,
				<DCC_READ 0x240e1010 2 0>,
				<DCC_LOOP 0x1 0 0>,
				<DCC_READ 0x240e1018 1 0>,
				<DCC_READ 0x245f0000 3 0>,
				<DCC_READ 0x245f0010  0>,
				<DCC_READ 0x245f0018  0>,
				<DCC_READ 0x245f0020 8 0>,
				<DCC_READ 0x245f0240  0>,
				<DCC_READ 0x245f0248  0>,
				<DCC_READ 0x245f2008  0>,
				<DCC_LOOP 0x3 0 0>,
				<DCC_READ 0x245f2010 2 0>,
				<DCC_LOOP 0x1 0 0>,
				<DCC_READ 0x245f2018  0>,
				<DCC_READ 0x247f0000 3 0>,
				<DCC_READ 0x247f0010  0>,
				<DCC_READ 0x247f0018  0>,
				<DCC_READ 0x247f0020 8 0>,
				<DCC_READ 0x247f0240  0>,
				<DCC_READ 0x247f0248  0>,
				<DCC_READ 0x247f2008  0>,
				<DCC_LOOP 0x3 0 0>,
				<DCC_READ 0x247f2010 2 0>,
				<DCC_LOOP 0x1 0 0>,
				<DCC_READ 0x247f2018  0>,
				<DCC_READ 0x1780008  0>,
				<DCC_READ 0x1780010  0>,
				<DCC_READ 0x1780018  0>,
				<DCC_READ 0x1780020 8 0>,
				<DCC_READ 0x1780240  0>,
				<DCC_READ 0x1780248  0>,
				<DCC_READ 0x17a5010  0>,
				<DCC_READ 0x17a6010  0>,
				<DCC_READ 0x17a7010  0>,
				<DCC_READ 0x17a8010  0>,
				<DCC_READ 0x17a9010  0>,
				<DCC_READ 0x17aa010  0>,
				<DCC_READ 0x17ab010  0>,
				<DCC_READ 0x17ac010  0>,
				<DCC_READ 0x17ad010  0>,
				<DCC_READ 0x1782208  0>,
				<DCC_LOOP 0x3 0 0>,
				<DCC_READ 0x1782210 2 >,
				<DCC_LOOP 0x1 0 0>,
				<DCC_READ 0x1782218  0>,
				<DCC_READ 0x1782308  0>,
				<DCC_LOOP 0x8 0 0>,
				<DCC_READ 0x1782310 2 0>,
				<DCC_LOOP 0x1 0 0>,
				<DCC_READ 0x1782318  0>,
				<DCC_READ 0x17c0008  0>,
				<DCC_READ 0x17c0010  0>,
				<DCC_READ 0x17c0018  0>,
				<DCC_READ 0x17c0020 8 0>,
				<DCC_READ 0x17c0240  0>,
				<DCC_READ 0x17c0248  0>,
				<DCC_READ 0x17e4010  0>,
				<DCC_READ 0x17e5010  0>,
				<DCC_READ 0x17e6010  0>,
				<DCC_READ 0x17e7010  0>,
				<DCC_READ 0x17e8010  0>,
				<DCC_READ 0x17e9010  0>,
				<DCC_READ 0x17c2008  0>,
				<DCC_LOOP 0x7 0 0>,
				<DCC_READ 0x17c2010 2 0>,
				<DCC_LOOP 0x1 0 0>,
				<DCC_READ 0x17c2018  0>,
				<DCC_READ 0x17c2108  0>,
				<DCC_LOOP 0x15 0 0>,
				<DCC_READ 0x17c2110 2 0>,
				<DCC_LOOP 0x1 0 0>,
				<DCC_READ 0x17c2118  0>,
				<DCC_READ 0x3c40008  0>,
				<DCC_READ 0x3c40010  0>,
				<DCC_READ 0x3c40018  0>,
				<DCC_READ 0x3c40020 8 0>,
				<DCC_READ 0x3c4b040  0>,
				<DCC_READ 0x3c4b048  0>,
				<DCC_READ 0x3c41008  0>,
				<DCC_LOOP 0x5 0 0>,
				<DCC_READ 0x3c41010 2 0>,
				<DCC_LOOP 0x1 0 0>,
				<DCC_READ 0x3c41018  0>,
				<DCC_READ 0x3c44008  0>,
				<DCC_READ 0x3c45008  0>,
				<DCC_READ 0x3c46008  0>,
				<DCC_READ 0x3c50008  0>,
				<DCC_READ 0x3c50010  0>,
				<DCC_READ 0x3c50018  0>,
				<DCC_READ 0x3c50020 8 0>,
				<DCC_READ 0x3c56040  0>,
				<DCC_READ 0x3c56048  0>,
				<DCC_READ 0x3c51008  0>,
				<DCC_LOOP 0x2 0 0>,
				<DCC_READ 0x3c51010 2 0>,
				<DCC_LOOP 0x1 0 0>,
				<DCC_READ 0x3c51018  0>,
				<DCC_READ 0x39c4008  0>,
				<DCC_READ 0x39c4010  0>,
				<DCC_READ 0x39c4018  0>,
				<DCC_READ 0x39c4020 8 0>,
				<DCC_READ 0x39c5010  0>,
				<DCC_READ 0x3c54008  0>,
				<DCC_READ 0x322f0000 3 0>,
				<DCC_READ 0x322f0010  0>,
				<DCC_READ 0x322f0018  0>,
				<DCC_READ 0x322f0020 8 0>,
				<DCC_READ 0x322f0240  0>,
				<DCC_READ 0x322f0248  0>,
				<DCC_READ 0x322f1008  0>,
				<DCC_LOOP 0x7 0 0>,
				<DCC_READ 0x322f1010 2 0>,
				<DCC_LOOP 0x1 0 0>,
				<DCC_READ 0x322f1018  0>,
				<DCC_READ 0x320c0008  0>,
				<DCC_READ 0x320c0010  0>,
				<DCC_READ 0x320c0018  0>,
				<DCC_READ 0x320c0020 8 0>,
				<DCC_READ 0x320c0240  0>,
				<DCC_READ 0x320c0248  0>,
				<DCC_READ 0x320c1008  0>,
				<DCC_LOOP 0x7 0 0>,
				<DCC_READ 0x320c1010 2 0>,
				<DCC_LOOP 0x1 0 0>,
				<DCC_READ 0x320c1018  0>,
				<DCC_READ 0x322fe010  0>,
				<DCC_READ 0x322fe090  0>,
				<DCC_READ 0x322fe110  0>,
				<DCC_READ 0x322fe190  0>,
				<DCC_READ 0x320d0010  0>,
				<DCC_READ 0x320d1010  0>,
				<DCC_READ 0x320d2010  0>,
				<DCC_READ 0x320d3010  0>,
				<DCC_READ 0x3da0074 1 0>,
				<DCC_READ 0x3da0474 1 0>,
				<DCC_READ 0x3da0070 1 0>,
				<DCC_READ 0x15000474 1 0>,
				<DCC_READ 0x15000074 1 0>,
				<DCC_READ 0x15000070 1 0>,
				<DCC_READ 0x17421000 2 0>;
		};
	};

	mem_dump {
		compatible = "qcom,mem-dump";
		memory-region = <&dump_mem>;

		c0_context {
			qcom,dump-size = <0x800>;
			qcom,dump-id = <0x0>;
		};

		c100_context {
			qcom,dump-size = <0x800>;
			qcom,dump-id = <0x1>;
		};

		c200_context {
			qcom,dump-size = <0x800>;
			qcom,dump-id = <0x2>;
		};

		c300_context {
			qcom,dump-size = <0x800>;
			qcom,dump-id = <0x3>;
		};

		c400_context {
			qcom,dump-size = <0x800>;
			qcom,dump-id = <0x4>;
		};

		c500_context {
			qcom,dump-size = <0x800>;
			qcom,dump-id = <0x5>;
		};

		c600_context {
			qcom,dump-size = <0x800>;
			qcom,dump-id = <0x6>;
		};

		c700_context {
			qcom,dump-size = <0x800>;
			qcom,dump-id = <0x7>;
		};

		l1_icache0 {
			qcom,dump-size = <0x27000>;
			qcom,dump-id = <0x60>;
		};

		l1_icache100 {
			qcom,dump-size = <0x27000>;
			qcom,dump-id = <0x61>;
		};

		l1_icache200 {
			qcom,dump-size = <0x27000>;
			qcom,dump-id = <0x62>;
		};

		l1_icache300 {
			qcom,dump-size = <0x27000>;
			qcom,dump-id = <0x63>;
		};

		l1_icache400 {
			qcom,dump-size = <0x27000>;
			qcom,dump-id = <0x64>;
		};

		l1_icache500 {
			qcom,dump-size = <0x27000>;
			qcom,dump-id = <0x65>;
		};

		l1_dcache0 {
			qcom,dump-size = <0x12800>;
			qcom,dump-id = <0x80>;
		};

		l1_dcache100 {
			qcom,dump-size = <0x12800>;
			qcom,dump-id = <0x81>;
		};

		l1_dcache200 {
			qcom,dump-size = <0x12800>;
			qcom,dump-id = <0x82>;
		};

		l1_dcache300 {
			qcom,dump-size = <0x12800>;
			qcom,dump-id = <0x83>;
		};

		l1_dcache400 {
			qcom,dump-size = <0x12800>;
			qcom,dump-id = <0x84>;
		};

		l1_dcache500 {
			qcom,dump-size = <0x12800>;
			qcom,dump-id = <0x85>;
		};

		l1_itlb500 {
			qcom,dump-size = <0x600>;
			qcom,dump-id = <0x25>;
		};

		l1_itlb600 {
			qcom,dump-size = <0x600>;
			qcom,dump-id = <0x26>;
		};

		l1_itlb700 {
			qcom,dump-size = <0x600>;
			qcom,dump-id = <0x27>;
		};

		l1_dtlb500 {
			qcom,dump-size = <0x600>;
			qcom,dump-id = <0x45>;
		};

		l1_dtlb600 {
			qcom,dump-size = <0x600>;
			qcom,dump-id = <0x46>;
		};

		l1_dtlb700 {
			qcom,dump-size = <0x600>;
			qcom,dump-id = <0x47>;
		};

		l2_cache0 {
			qcom,dump-size = <0x93800>;
			qcom,dump-id = <0xc0>;
		};

		l2_cache100 {
			qcom,dump-size = <0x93800>;
			qcom,dump-id = <0xc1>;
		};

		l2_cache200 {
			qcom,dump-size = <0x93800>;
			qcom,dump-id = <0xc2>;
		};

		l2_cache300 {
			qcom,dump-size = <0x93800>;
			qcom,dump-id = <0xc3>;
		};

		l2_cache400 {
			qcom,dump-size = <0x93800>;
			qcom,dump-id = <0xc4>;
		};

		l2_cache500 {
			qcom,dump-size = <0x93800>;
			qcom,dump-id = <0xc5>;
		};

		l2_tlb0 {
			qcom,dump-size = <0xf700>;
			qcom,dump-id = <0x120>;
		};

		l2_tlb100 {
			qcom,dump-size = <0xf700>;
			qcom,dump-id = <0x121>;
		};

		l2_tlb200 {
			qcom,dump-size = <0xf700>;
			qcom,dump-id = <0x122>;
		};

		l2_tlb500 {
			qcom,dump-size = <0x7900>;
			qcom,dump-id = <0x125>;
		};

		l2_tlb600 {
			qcom,dump-size = <0x7900>;
			qcom,dump-id = <0x126>;
		};

		l2_tlb700 {
			qcom,dump-size = <0xa900>;
			qcom,dump-id = <0x127>;
		};

		l1dcdirty0 {
			qcom,dump-size = <0x1100>;
			qcom,dump-id = <0x170>;
		};

		l1dcdirty100 {
			qcom,dump-size = <0x1100>;
			qcom,dump-id = <0x171>;
		};

		l1dcdirty200 {
			qcom,dump-size = <0x1100>;
			qcom,dump-id = <0x172>;
		};

		l1dcmte0 {
			qcom,dump-size = <0x1100>;
			qcom,dump-id = <0x180>;
		};

		l1dcmte100 {
			qcom,dump-size = <0x1100>;
			qcom,dump-id = <0x181>;
		};

		l1dcmte200 {
			qcom,dump-size = <0x1100>;
			qcom,dump-id = <0x182>;
		};

		l2dcmte0 {
			qcom,dump-size = <0x4100>;
			qcom,dump-id = <0x190>;
		};

		l2dcmte100 {
			qcom,dump-size = <0x4100>;
			qcom,dump-id = <0x191>;
		};

		l2dcmte200 {
			qcom,dump-size = <0x4100>;
			qcom,dump-id = <0x192>;
		};

		l0mopca500 {
			qcom,dump-size = <0x4100>;
			qcom,dump-id = <0x1a5>;
		};

		l0mopca600 {
			qcom,dump-size = <0x4100>;
			qcom,dump-id = <0x1a6>;
		};

		l0mopca700 {
			qcom,dump-size = <0x4100>;
			qcom,dump-id = <0x1a7>;
		};

		l1btb500 {
			qcom,dump-size = <0x10100>;
			qcom,dump-id = <0x1b5>;
		};

		l1btb600 {
			qcom,dump-size = <0x10100>;
			qcom,dump-id = <0x1b6>;
		};

		l1ghb500 {
			qcom,dump-size = <0x4100>;
			qcom,dump-id = <0x1c5>;
		};

		l1ghb600 {
			qcom,dump-size = <0x4100>;
			qcom,dump-id = <0x1c6>;
		};

		l1bim500 {
			qcom,dump-size = <0x2100>;
			qcom,dump-id = <0x1d5>;
		};

		l1bim600 {
			qcom,dump-size = <0x2100>;
			qcom,dump-id = <0x1d6>;
		};

		l2victim500 {
			qcom,dump-size = <0x2100>;
			qcom,dump-id = <0x1e5>;
		};

		l2victim600 {
			qcom,dump-size = <0x2100>;
			qcom,dump-id = <0x1e6>;
		};

		l2victim700 {
			qcom,dump-size = <0x2100>;
			qcom,dump-id = <0x1e7>;
		};

		l2tldtcsp300 {
			qcom,dump-size = <0x7900>;
			qcom,dump-id = <0x203>;
		};

		l2tldtcsp400 {
			qcom,dump-size = <0x7900>;
			qcom,dump-id = <0x204>;
		};

		l2tldtcmp300 {
			qcom,dump-size = <0x1300>;
			qcom,dump-id = <0x213>;
		};

		l2tldtcmp400 {
			qcom,dump-size = <0x1300>;
			qcom,dump-id = <0x214>;
		};

		cpuss_reg {
			qcom,dump-size = <0x30000>;
			qcom,dump-id = <0xef>;
		};

		gemnoc {
			qcom,dump-size = <0x100000>;
			qcom,dump-id = <0x162>;
		};

		rpmh {
			qcom,dump-size = <0x400000>;
			qcom,dump-id = <0xec>;
		};

		rpm_sw {
			qcom,dump-size = <0x28000>;
			qcom,dump-id = <0xea>;
		};

		pmic {
			qcom,dump-size = <0x200000>;
			qcom,dump-id = <0xe4>;
		};

		fcm {
			qcom,dump-size = <0x8400>;
			qcom,dump-id = <0xee>;
		};

		etf_swao {
			qcom,dump-size = <0x10000>;
			qcom,dump-id = <0xf1>;
		};

		etr_reg {
			qcom,dump-size = <0x1000>;
			qcom,dump-id = <0x100>;
		};

		etfswao_reg {
			qcom,dump-size = <0x1000>;
			qcom,dump-id = <0x102>;
		};

		etr1_reg {
			qcom,dump-size = <0x1000>;
			qcom,dump-id = <0x105>;
		};

		misc_data {
			qcom,dump-size = <0x1000>;
			qcom,dump-id = <0xe8>;
		};

		etf_slpi {
			qcom,dump-size = <0x4000>;
			qcom,dump-id = <0xf3>;
		};

		etfslpi_reg {
			qcom,dump-size = <0x1000>;
			qcom,dump-id = <0x103>;
		};

		etf_lpass {
			qcom,dump-size = <0x4000>;
			qcom,dump-id = <0xf4>;
		};

		etflpass_reg {
			qcom,dump-size = <0x1000>;
			qcom,dump-id = <0x104>;
		};

		llcc1dc {
			qcom,dump-size = <0x171000>;
			qcom,dump-id = <0x140>;
		};

		llcc2dc {
			qcom,dump-size = <0x171000>;
			qcom,dump-id = <0x141>;
		};

		llcc3dc {
			qcom,dump-size = <0x171000>;
			qcom,dump-id = <0x142>;
		};

		llcc4dc {
			qcom,dump-size = <0x171000>;
			qcom,dump-id = <0x143>;
		};

		osm_reg {
			qcom,dump-size = <0x400>;
			qcom,dump-id = <0x163>;
		};

		pcu_reg {
			qcom,dump-size = <0x400>;
			qcom,dump-id = <0x164>;
		};

		fsm_data {
			qcom,dump-size = <0x400>;
			qcom,dump-id = <0x165>;
		};
	};
};
